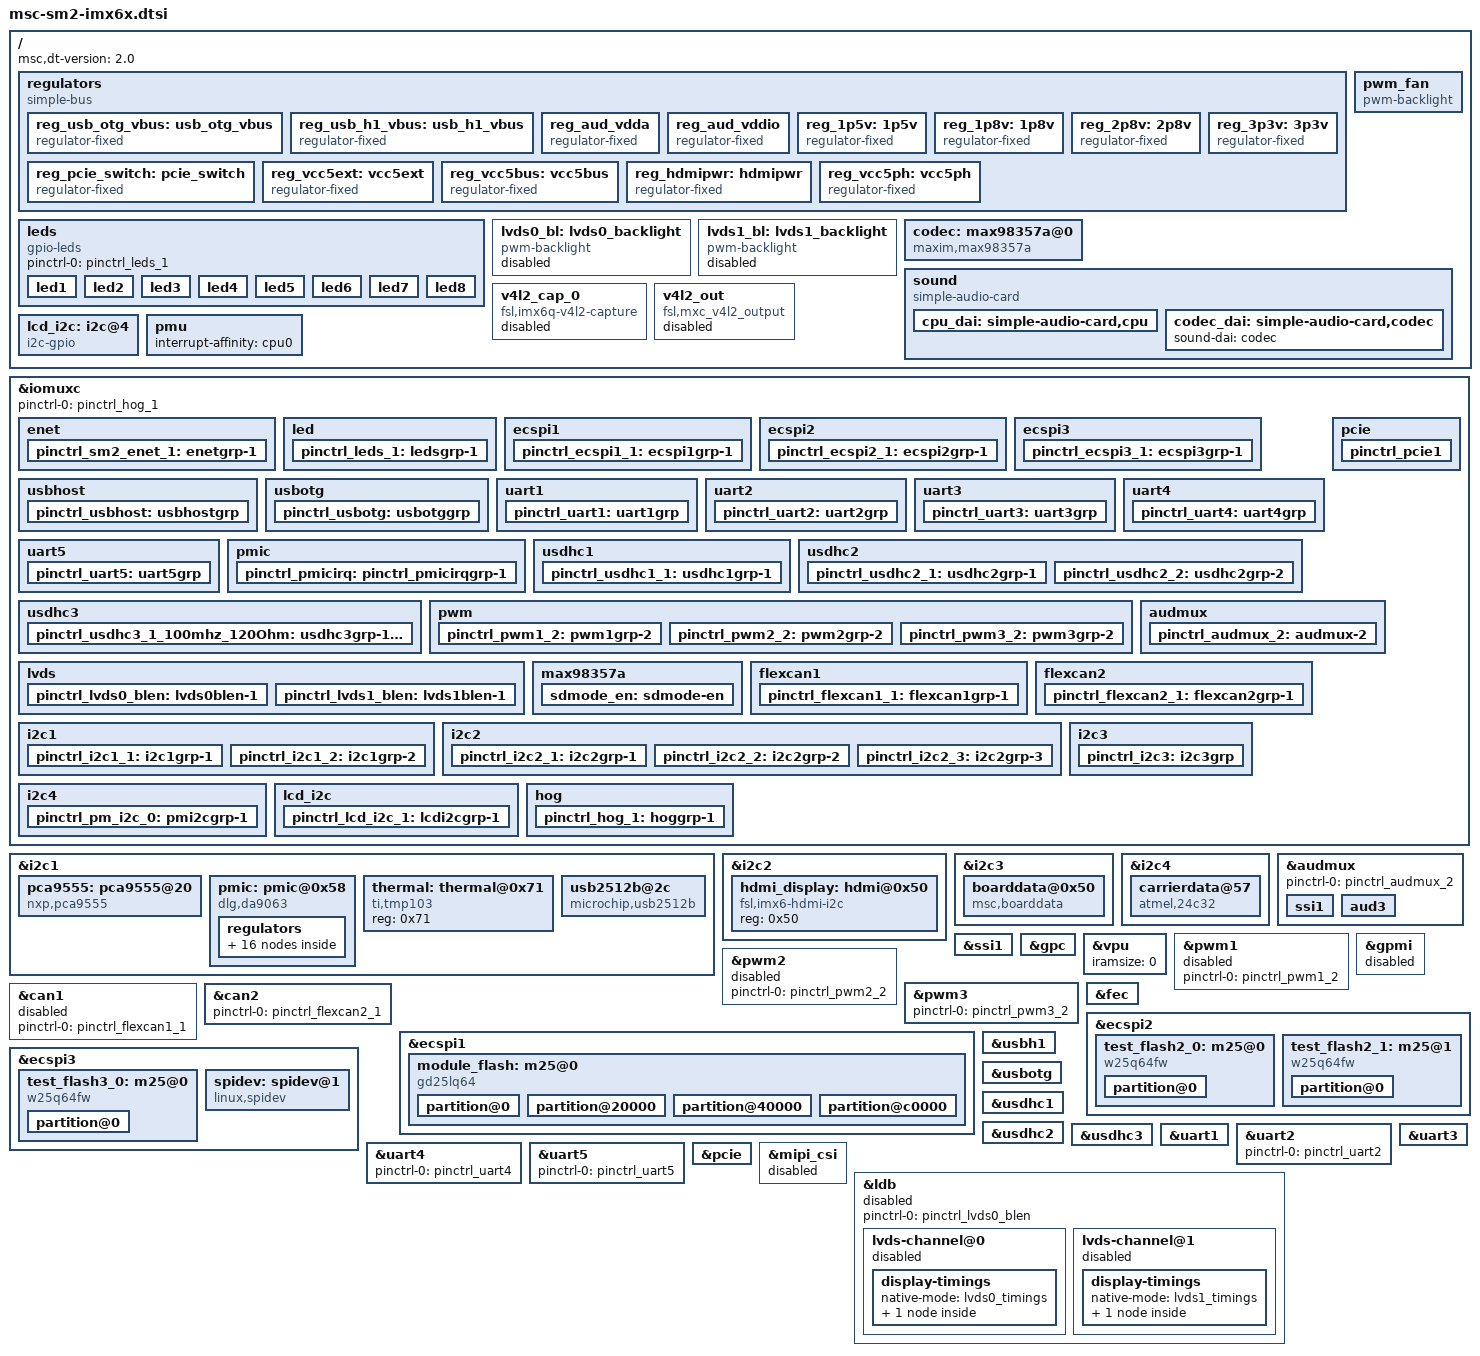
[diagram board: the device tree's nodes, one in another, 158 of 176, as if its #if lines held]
/*
 * Copyright 2017 MSC Technologies GmbH
 *
 * The code contained herein is licensed under the GNU General Public
 * License. You may obtain a copy of the GNU General Public License
 * Version 2 or later at the following locations:
 *
 * http://www.opensource.org/licenses/gpl-license.html
 * http://www.gnu.org/copyleft/gpl.html
 */

#include "skeleton.dtsi"
#include <dt-bindings/gpio/gpio.h>
#include <dt-bindings/sound/fsl-imx-audmux.h>


/* TODO: Find a suitable place for the macros below */
#define IMX_NO_PAD_CTL		(1 << 31)	/* Handled by mux driver: No pin config need */
#define IMX_PAD_SION		(1 << 30)	/* Handled by mux driver: Set SION */

#define PAD__HYS__DIS		(0 << 16)	/* CMOS input */
#define PAD__HYS__EN		(1 << 16)	/* Scmhitt trigger input */

#define PAD__PUS__100K_OHM_PD	(0 << 14)	/* 100K Ohm pull down */
#define PAD__PUS__47K_OHM_PU	(1 << 14)	/*  47K Ohm pull up */
#define PAD__PUS__100K_OHM_PU	(2 << 14)	/* 100K Ohm pull up */
#define PAD__PUS__22K_OHM_PU	(3 << 14)	/*  22K Ohm pull up */

#define PAD__PUE__KEEP		(0 << 13)	/* Keeper enabled */
#define PAD__PUE__PULL		(1 << 13)	/* Pull enabled */

#define PAD__PKE__DIS		(0 << 12)	/* Pull/Keeper disabled */
#define PAD__PKE__EN		(1 << 12)	/* Pull/Keeper enabled */

#define PAD__ODE__DIS		(0 << 11)	/* Output is CMOS */
#define PAD__ODE__EN		(1 << 11)	/* Output is Open Drain */

#define PAD__SPEED__LOW		(0 <<  6)	/*  50 MHz (SRE=x) */
#define PAD__SPEED__MEDIUM1	(1 <<  6)	/* 100 MHz, if SRE=1: 100MHz @ 1.8V, 150MHz @ 3.3V */
#define PAD__SPEED__MEDIUM2	(2 <<  6)	/* 100 MHz, if SRE=1: 100MHz @ 1.8V, 150MHz @ 3.3V */
#define PAD__SPEED__MAXIMUM	(3 <<  6)	/* 100 MHz, if SRE=1: 150MHz @ 1.8V, 100MHz @ 3.3V */

#define PAD__DSE__HIZ		(0 <<  3)	/* Hi-Z */
#define PAD__DSE__260_OHM	(1 <<  3)	/* 157 Ohm @ 3.3V, 260 Ohm @ 1.8V */
#define PAD__DSE__130_OHM	(2 <<  3)	/*  78 Ohm @ 3.3V, 130 Ohm @ 1.8V */
#define PAD__DSE__88_OHM	(3 <<  3)	/*  53 Ohm @ 3.3V,  88 Ohm @ 1.8V */
#define PAD__DSE__65_OHM	(4 <<  3)	/*  39 Ohm @ 3.3V,  65 Ohm @ 1.8V */
#define PAD__DSE__52_OHM	(5 <<  3)	/*  32 Ohm @ 3.3V,  52 Ohm @ 1.8V */
#define PAD__DSE__43_OHM	(6 <<  3)	/*  26 Ohm @ 3.3V,  43 Ohm @ 1.8V */
#define PAD__DSE__37_OHM	(7 <<  3)	/*  23 Ohm @ 3.3V,  37 Ohm @ 1.8V */

#define PAD__SRE__SLOW		(0 <<  0)	/* Slow slew rate */
#define PAD__SRE__FAST		(1 <<  0)	/* Fast slew rate */


&iomuxc {
	enet {
		pinctrl_sm2_enet_1: enetgrp-1 {
			fsl,pins = <
				MX6QDL_PAD_ENET_MDIO__ENET_MDIO		(PAD__HYS__EN  | PAD__PUS__100K_OHM_PU | PAD__PUE__PULL | PAD__PKE__EN  | PAD__ODE__DIS | PAD__SPEED__MEDIUM2 | PAD__DSE__43_OHM  | PAD__SRE__SLOW)
				MX6QDL_PAD_ENET_MDC__ENET_MDC		(PAD__HYS__EN  | PAD__PUS__100K_OHM_PU | PAD__PUE__PULL | PAD__PKE__EN  | PAD__ODE__DIS | PAD__SPEED__MEDIUM2 | PAD__DSE__43_OHM  | PAD__SRE__SLOW)
				MX6QDL_PAD_RGMII_TXC__RGMII_TXC		(PAD__HYS__EN  | PAD__PUS__100K_OHM_PU | PAD__PUE__PULL | PAD__PKE__EN  | PAD__ODE__DIS | PAD__SPEED__MEDIUM2 | PAD__DSE__43_OHM  | PAD__SRE__SLOW)
				MX6QDL_PAD_RGMII_TD0__RGMII_TD0		(PAD__HYS__EN  | PAD__PUS__100K_OHM_PU | PAD__PUE__PULL | PAD__PKE__EN  | PAD__ODE__DIS | PAD__SPEED__MEDIUM2 | PAD__DSE__43_OHM  | PAD__SRE__SLOW)
				MX6QDL_PAD_RGMII_TD1__RGMII_TD1		(PAD__HYS__EN  | PAD__PUS__100K_OHM_PU | PAD__PUE__PULL | PAD__PKE__EN  | PAD__ODE__DIS | PAD__SPEED__MEDIUM2 | PAD__DSE__43_OHM  | PAD__SRE__SLOW)
				MX6QDL_PAD_RGMII_TD2__RGMII_TD2		(PAD__HYS__EN  | PAD__PUS__100K_OHM_PU | PAD__PUE__PULL | PAD__PKE__EN  | PAD__ODE__DIS | PAD__SPEED__MEDIUM2 | PAD__DSE__43_OHM  | PAD__SRE__SLOW)
				MX6QDL_PAD_RGMII_TD3__RGMII_TD3		(PAD__HYS__EN  | PAD__PUS__100K_OHM_PU | PAD__PUE__PULL | PAD__PKE__EN  | PAD__ODE__DIS | PAD__SPEED__MEDIUM2 | PAD__DSE__43_OHM  | PAD__SRE__SLOW)
				MX6QDL_PAD_RGMII_TX_CTL__RGMII_TX_CTL	(PAD__HYS__EN  | PAD__PUS__100K_OHM_PU | PAD__PUE__PULL | PAD__PKE__EN  | PAD__ODE__DIS | PAD__SPEED__MEDIUM2 | PAD__DSE__43_OHM  | PAD__SRE__SLOW)
				MX6QDL_PAD_ENET_REF_CLK__ENET_TX_CLK	(PAD__HYS__EN  | PAD__PUS__100K_OHM_PD | PAD__PUE__KEEP | PAD__PKE__DIS | PAD__ODE__DIS | PAD__SPEED__MEDIUM2 | PAD__DSE__43_OHM  | PAD__SRE__SLOW)
				MX6QDL_PAD_RGMII_RXC__RGMII_RXC		(PAD__HYS__EN  | PAD__PUS__100K_OHM_PU | PAD__PUE__PULL | PAD__PKE__EN  | PAD__ODE__DIS | PAD__SPEED__MEDIUM2 | PAD__DSE__43_OHM  | PAD__SRE__SLOW)
				MX6QDL_PAD_RGMII_RD0__RGMII_RD0		(PAD__HYS__EN  | PAD__PUS__100K_OHM_PU | PAD__PUE__PULL | PAD__PKE__EN  | PAD__ODE__DIS | PAD__SPEED__MEDIUM2 | PAD__DSE__43_OHM  | PAD__SRE__SLOW)
				MX6QDL_PAD_RGMII_RD1__RGMII_RD1		(PAD__HYS__EN  | PAD__PUS__100K_OHM_PU | PAD__PUE__PULL | PAD__PKE__EN  | PAD__ODE__DIS | PAD__SPEED__MEDIUM2 | PAD__DSE__43_OHM  | PAD__SRE__SLOW)
				MX6QDL_PAD_RGMII_RD2__RGMII_RD2		(PAD__HYS__EN  | PAD__PUS__100K_OHM_PU | PAD__PUE__PULL | PAD__PKE__EN  | PAD__ODE__DIS | PAD__SPEED__MEDIUM2 | PAD__DSE__43_OHM  | PAD__SRE__SLOW)
				MX6QDL_PAD_RGMII_RD3__RGMII_RD3		(PAD__HYS__EN  | PAD__PUS__100K_OHM_PU | PAD__PUE__PULL | PAD__PKE__EN  | PAD__ODE__DIS | PAD__SPEED__MEDIUM2 | PAD__DSE__43_OHM  | PAD__SRE__SLOW)
				MX6QDL_PAD_RGMII_RX_CTL__RGMII_RX_CTL	(PAD__HYS__EN  | PAD__PUS__100K_OHM_PU | PAD__PUE__PULL | PAD__PKE__EN  | PAD__ODE__DIS | PAD__SPEED__MEDIUM2 | PAD__DSE__43_OHM  | PAD__SRE__SLOW)
			>;
		};
	};

	led {
		pinctrl_leds_1: ledsgrp-1 {
			fsl,pins = <
				MX6QDL_PAD_NANDF_D3__GPIO2_IO03		(PAD__HYS__DIS | PAD__PUS__100K_OHM_PD | PAD__PUE__KEEP | PAD__PKE__DIS | PAD__ODE__DIS | PAD__SPEED__LOW     | PAD__DSE__HIZ     | PAD__SRE__SLOW | IMX_NO_PAD_CTL)	/* DEBUG_0 on SoM debug connector */
				MX6QDL_PAD_NANDF_D4__GPIO2_IO04		(PAD__HYS__DIS | PAD__PUS__100K_OHM_PD | PAD__PUE__KEEP | PAD__PKE__DIS | PAD__ODE__DIS | PAD__SPEED__LOW     | PAD__DSE__HIZ     | PAD__SRE__SLOW | IMX_NO_PAD_CTL)	/* DEBUG_1 on SoM debug connector */
				MX6QDL_PAD_NANDF_D5__GPIO2_IO05		(PAD__HYS__DIS | PAD__PUS__100K_OHM_PD | PAD__PUE__KEEP | PAD__PKE__DIS | PAD__ODE__DIS | PAD__SPEED__LOW     | PAD__DSE__HIZ     | PAD__SRE__SLOW | IMX_NO_PAD_CTL)	/* DEBUG_2 on SoM debug connector */
				MX6QDL_PAD_ENET_CRS_DV__GPIO1_IO25	(PAD__HYS__DIS | PAD__PUS__100K_OHM_PD | PAD__PUE__KEEP | PAD__PKE__DIS | PAD__ODE__DIS | PAD__SPEED__LOW     | PAD__DSE__HIZ     | PAD__SRE__SLOW | IMX_NO_PAD_CTL)	/* iMX6 U21,                             Linux GPIO  25, SoM Orange LED */
				MX6QDL_PAD_KEY_COL1__GPIO4_IO08		(PAD__HYS__DIS | PAD__PUS__100K_OHM_PD | PAD__PUE__KEEP | PAD__PKE__DIS | PAD__ODE__DIS | PAD__SPEED__LOW     | PAD__DSE__HIZ     | PAD__SRE__SLOW | IMX_NO_PAD_CTL)	/* iMX6  U7, SoM  S54, SMARC2 SATA_ACT#, Linux GPIO 104 */
				MX6QDL_PAD_EIM_D29__GPIO3_IO29		(PAD__HYS__DIS | PAD__PUS__100K_OHM_PD | PAD__PUE__PULL | PAD__PKE__EN  | PAD__ODE__DIS | PAD__SPEED__MEDIUM2 | PAD__DSE__43_OHM  | PAD__SRE__FAST)		/* iMX6 J19, SoM P108, SMARC2 GPIO0,     Linux GPIO  93, Carrier board LED0 */
				MX6QDL_PAD_GPIO_16__GPIO7_IO11		(PAD__HYS__DIS | PAD__PUS__100K_OHM_PD | PAD__PUE__PULL | PAD__PKE__EN  | PAD__ODE__DIS | PAD__SPEED__MEDIUM2 | PAD__DSE__43_OHM  | PAD__SRE__FAST)		/* iMX6  R2, SoM P109, SMARC2 GPIO1,     Linux GPIO 203, Carrier board LED1 */
				MX6QDL_PAD_EIM_D28__GPIO3_IO28		(PAD__HYS__DIS | PAD__PUS__100K_OHM_PD | PAD__PUE__PULL | PAD__PKE__EN  | PAD__ODE__DIS | PAD__SPEED__MEDIUM2 | PAD__DSE__43_OHM  | PAD__SRE__FAST)		/* iMX6 G23, SoM P110, SMARC2 GPIO2,     Linux GPIO  92, Carrier board LED2 */
			>;
		};
	};

	ecspi1 {
		pinctrl_ecspi1_1: ecspi1grp-1 {
			fsl,pins = <
				MX6QDL_PAD_EIM_D17__ECSPI1_MISO		(PAD__HYS__EN  | PAD__PUS__100K_OHM_PD | PAD__PUE__KEEP | PAD__PKE__DIS | PAD__ODE__DIS | PAD__SPEED__MEDIUM2 | PAD__DSE__43_OHM  | PAD__SRE__FAST)
				MX6QDL_PAD_EIM_D18__ECSPI1_MOSI		(PAD__HYS__EN  | PAD__PUS__100K_OHM_PD | PAD__PUE__KEEP | PAD__PKE__DIS | PAD__ODE__DIS | PAD__SPEED__MEDIUM2 | PAD__DSE__43_OHM  | PAD__SRE__FAST)
				MX6QDL_PAD_EIM_D16__ECSPI1_SCLK		(PAD__HYS__EN  | PAD__PUS__100K_OHM_PD | PAD__PUE__KEEP | PAD__PKE__DIS | PAD__ODE__DIS | PAD__SPEED__MEDIUM2 | PAD__DSE__43_OHM  | PAD__SRE__FAST)
				MX6QDL_PAD_EIM_EB2__GPIO2_IO30		(PAD__HYS__DIS | PAD__PUS__100K_OHM_PD | PAD__PUE__PULL | PAD__PKE__EN  | PAD__ODE__DIS | PAD__SPEED__MEDIUM2 | PAD__DSE__43_OHM  | PAD__SRE__FAST)		/* SPI1_SS0n */
			>;
		};
	};

	ecspi2 {
		pinctrl_ecspi2_1: ecspi2grp-1 {
			fsl,pins = <
				MX6QDL_PAD_EIM_OE__ECSPI2_MISO		(PAD__HYS__EN  | PAD__PUS__100K_OHM_PD | PAD__PUE__KEEP | PAD__PKE__DIS | PAD__ODE__DIS | PAD__SPEED__MEDIUM2 | PAD__DSE__43_OHM  | PAD__SRE__FAST)
				MX6QDL_PAD_EIM_CS1__ECSPI2_MOSI		(PAD__HYS__EN  | PAD__PUS__100K_OHM_PD | PAD__PUE__KEEP | PAD__PKE__DIS | PAD__ODE__DIS | PAD__SPEED__MEDIUM2 | PAD__DSE__43_OHM  | PAD__SRE__FAST)
				MX6QDL_PAD_EIM_CS0__ECSPI2_SCLK		(PAD__HYS__EN  | PAD__PUS__100K_OHM_PD | PAD__PUE__KEEP | PAD__PKE__DIS | PAD__ODE__DIS | PAD__SPEED__MEDIUM2 | PAD__DSE__43_OHM  | PAD__SRE__FAST)
				MX6QDL_PAD_DISP0_DAT18__GPIO5_IO12	(PAD__HYS__DIS | PAD__PUS__100K_OHM_PD | PAD__PUE__PULL | PAD__PKE__EN  | PAD__ODE__DIS | PAD__SPEED__MEDIUM2 | PAD__DSE__43_OHM  | PAD__SRE__FAST)		/* SPI2_SS0n */
				MX6QDL_PAD_DISP0_DAT15__GPIO5_IO09	(PAD__HYS__DIS | PAD__PUS__100K_OHM_PD | PAD__PUE__PULL | PAD__PKE__EN  | PAD__ODE__DIS | PAD__SPEED__MEDIUM2 | PAD__DSE__43_OHM  | PAD__SRE__FAST)		/* SPI2_SS1n */
			>;
		};
	};

	ecspi3 {
		pinctrl_ecspi3_1: ecspi3grp-1 {
			fsl,pins = <
				MX6QDL_PAD_DISP0_DAT2__ECSPI3_MISO	(PAD__HYS__EN  | PAD__PUS__100K_OHM_PD | PAD__PUE__KEEP | PAD__PKE__DIS | PAD__ODE__DIS | PAD__SPEED__MEDIUM2 | PAD__DSE__43_OHM  | PAD__SRE__FAST)
				MX6QDL_PAD_DISP0_DAT1__ECSPI3_MOSI	(PAD__HYS__EN  | PAD__PUS__100K_OHM_PD | PAD__PUE__KEEP | PAD__PKE__DIS | PAD__ODE__DIS | PAD__SPEED__MEDIUM2 | PAD__DSE__43_OHM  | PAD__SRE__FAST)
				MX6QDL_PAD_DISP0_DAT0__ECSPI3_SCLK	(PAD__HYS__EN  | PAD__PUS__100K_OHM_PD | PAD__PUE__KEEP | PAD__PKE__DIS | PAD__ODE__DIS | PAD__SPEED__MEDIUM2 | PAD__DSE__43_OHM  | PAD__SRE__FAST)
				MX6QDL_PAD_DISP0_DAT3__GPIO4_IO24	(PAD__HYS__DIS | PAD__PUS__100K_OHM_PD | PAD__PUE__PULL | PAD__PKE__EN  | PAD__ODE__DIS | PAD__SPEED__MEDIUM2 | PAD__DSE__43_OHM  | PAD__SRE__FAST)		/* SPI3_SS0n */
				MX6QDL_PAD_DISP0_DAT4__GPIO4_IO25	(PAD__HYS__DIS | PAD__PUS__100K_OHM_PD | PAD__PUE__PULL | PAD__PKE__EN  | PAD__ODE__DIS | PAD__SPEED__MEDIUM2 | PAD__DSE__43_OHM  | PAD__SRE__FAST)		/* SPI3_SS1n */
			>;
		};
	};

	usbhost {
		pinctrl_usbhost: usbhostgrp {
			fsl,pins = <
				MX6QDL_PAD_GPIO_0__GPIO1_IO00		(PAD__HYS__EN  | PAD__PUS__100K_OHM_PU | PAD__PUE__PULL | PAD__PKE__EN  | PAD__ODE__EN  | PAD__SPEED__MEDIUM2 | PAD__DSE__43_OHM  | PAD__SRE__FAST)		/* iMX6 T5, SoM P67, SMARC2 USB1_EN_OC#, Linux GPIO 0, Output to switch external power enable */
				MX6QDL_PAD_GPIO_3__XTALOSC_REF_CLK_24M	(PAD__HYS__EN  | PAD__PUS__100K_OHM_PU | PAD__PUE__PULL | PAD__PKE__EN  | PAD__ODE__DIS | PAD__SPEED__LOW     | PAD__DSE__43_OHM  | PAD__SRE__SLOW)		/* USB_REFCLK */
				MX6QDL_PAD_EIM_D30__GPIO3_IO30		(PAD__HYS__EN  | PAD__PUS__100K_OHM_PU | PAD__PUE__PULL | PAD__PKE__EN  | PAD__ODE__EN  | PAD__SPEED__MEDIUM2 | PAD__DSE__43_OHM  | PAD__SRE__FAST)		/* iMX6 J20, SoM P67, SMARC2 USB1_EN_OC#, Linux GPIO 94, Input to monitor external power over-current */
			>;
		};
	};

	usbotg {
		pinctrl_usbotg: usbotggrp {
			fsl,pins = <
				MX6QDL_PAD_EIM_D22__GPIO3_IO22		(PAD__HYS__DIS | PAD__PUS__100K_OHM_PD | PAD__PUE__PULL | PAD__PKE__EN  | PAD__ODE__DIS | PAD__SPEED__MEDIUM2 | PAD__DSE__43_OHM  | PAD__SRE__FAST)		/* OTG_DRVVBUS */
				MX6QDL_PAD_ENET_RX_ER__USB_OTG_ID	(PAD__HYS__EN  | PAD__PUS__47K_OHM_PU  | PAD__PUE__PULL | PAD__PKE__EN  | PAD__ODE__DIS | PAD__SPEED__MEDIUM1 | PAD__DSE__88_OHM  | PAD__SRE__FAST)
				MX6QDL_PAD_EIM_D21__USB_OTG_OC		(PAD__HYS__EN  | PAD__PUS__100K_OHM_PU | PAD__PUE__PULL | PAD__PKE__EN  | PAD__ODE__DIS | PAD__SPEED__MEDIUM2 | PAD__DSE__43_OHM  | PAD__SRE__SLOW)
			>;
		};
	};

	uart1 {
		pinctrl_uart1: uart1grp {
			fsl,pins = <
				MX6QDL_PAD_CSI0_DAT10__UART1_TX_DATA	(PAD__HYS__EN  | PAD__PUS__100K_OHM_PU | PAD__PUE__PULL | PAD__PKE__EN  | PAD__ODE__DIS | PAD__SPEED__MEDIUM2 | PAD__DSE__43_OHM  | PAD__SRE__FAST)
				MX6QDL_PAD_CSI0_DAT11__UART1_RX_DATA	(PAD__HYS__EN  | PAD__PUS__100K_OHM_PU | PAD__PUE__PULL | PAD__PKE__EN  | PAD__ODE__DIS | PAD__SPEED__MEDIUM2 | PAD__DSE__43_OHM  | PAD__SRE__FAST)
				MX6QDL_PAD_EIM_D19__UART1_CTS_B		(PAD__HYS__EN  | PAD__PUS__100K_OHM_PU | PAD__PUE__PULL | PAD__PKE__EN  | PAD__ODE__DIS | PAD__SPEED__MEDIUM2 | PAD__DSE__43_OHM  | PAD__SRE__FAST)
				MX6QDL_PAD_EIM_D20__UART1_RTS_B		(PAD__HYS__EN  | PAD__PUS__100K_OHM_PU | PAD__PUE__PULL | PAD__PKE__EN  | PAD__ODE__DIS | PAD__SPEED__MEDIUM2 | PAD__DSE__43_OHM  | PAD__SRE__FAST)
			>;
		};
	};

	uart2 {
		pinctrl_uart2: uart2grp {
			fsl,pins = <
				MX6QDL_PAD_EIM_D26__UART2_TX_DATA	(PAD__HYS__EN  | PAD__PUS__100K_OHM_PU | PAD__PUE__PULL | PAD__PKE__EN  | PAD__ODE__DIS | PAD__SPEED__MEDIUM2 | PAD__DSE__43_OHM  | PAD__SRE__FAST)
				MX6QDL_PAD_EIM_D27__UART2_RX_DATA	(PAD__HYS__EN  | PAD__PUS__100K_OHM_PU | PAD__PUE__PULL | PAD__PKE__EN  | PAD__ODE__DIS | PAD__SPEED__MEDIUM2 | PAD__DSE__43_OHM  | PAD__SRE__FAST)
			>;
		};
	};

	uart3 {
		pinctrl_uart3: uart3grp {
			fsl,pins = <
				MX6QDL_PAD_EIM_D24__UART3_TX_DATA	(PAD__HYS__EN  | PAD__PUS__100K_OHM_PU | PAD__PUE__PULL | PAD__PKE__EN  | PAD__ODE__DIS | PAD__SPEED__MEDIUM2 | PAD__DSE__43_OHM  | PAD__SRE__FAST)
				MX6QDL_PAD_EIM_D25__UART3_RX_DATA	(PAD__HYS__EN  | PAD__PUS__100K_OHM_PU | PAD__PUE__PULL | PAD__PKE__EN  | PAD__ODE__DIS | PAD__SPEED__MEDIUM2 | PAD__DSE__43_OHM  | PAD__SRE__FAST)
				MX6QDL_PAD_EIM_D23__UART3_CTS_B		(PAD__HYS__EN  | PAD__PUS__100K_OHM_PU | PAD__PUE__PULL | PAD__PKE__EN  | PAD__ODE__DIS | PAD__SPEED__MEDIUM2 | PAD__DSE__43_OHM  | PAD__SRE__FAST)
				MX6QDL_PAD_EIM_D31__UART3_RTS_B		(PAD__HYS__EN  | PAD__PUS__100K_OHM_PU | PAD__PUE__PULL | PAD__PKE__EN  | PAD__ODE__DIS | PAD__SPEED__MEDIUM2 | PAD__DSE__43_OHM  | PAD__SRE__FAST)
			>;
		};
	};

	uart4 {
		pinctrl_uart4: uart4grp {
			fsl,pins = <
				MX6QDL_PAD_KEY_COL0__UART4_TX_DATA	(PAD__HYS__EN  | PAD__PUS__100K_OHM_PU | PAD__PUE__PULL | PAD__PKE__EN  | PAD__ODE__DIS | PAD__SPEED__MEDIUM2 | PAD__DSE__43_OHM  | PAD__SRE__FAST)
				MX6QDL_PAD_KEY_ROW0__UART4_RX_DATA	(PAD__HYS__EN  | PAD__PUS__100K_OHM_PU | PAD__PUE__PULL | PAD__PKE__EN  | PAD__ODE__DIS | PAD__SPEED__MEDIUM2 | PAD__DSE__43_OHM  | PAD__SRE__FAST)
			>;
		};
	};

	uart5 {
		pinctrl_uart5: uart5grp {
			fsl,pins = <
				MX6QDL_PAD_CSI0_DAT14__UART5_TX_DATA	(PAD__HYS__EN  | PAD__PUS__100K_OHM_PU | PAD__PUE__PULL | PAD__PKE__EN  | PAD__ODE__DIS | PAD__SPEED__MEDIUM2 | PAD__DSE__43_OHM  | PAD__SRE__FAST)
				MX6QDL_PAD_CSI0_DAT15__UART5_RX_DATA	(PAD__HYS__EN  | PAD__PUS__100K_OHM_PU | PAD__PUE__PULL | PAD__PKE__EN  | PAD__ODE__DIS | PAD__SPEED__MEDIUM2 | PAD__DSE__43_OHM  | PAD__SRE__FAST)
			>;
		};
	};

	pmic {
		pinctrl_pmicirq: pinctrl_pmicirqgrp-1 {
			fsl,pins = <
				MX6QDL_PAD_GPIO_4__GPIO1_IO04		(PAD__HYS__EN  | PAD__PUS__22K_OHM_PU  | PAD__PUE__PULL | PAD__PKE__EN  | PAD__ODE__DIS | PAD__SPEED__MEDIUM2 | PAD__DSE__43_OHM  | PAD__SRE__SLOW)
			>;
		};
	};

	usdhc1 {
		pinctrl_usdhc1_1: usdhc1grp-1 {
			fsl,pins = <
				MX6QDL_PAD_SD1_CMD__SD1_CMD		(PAD__HYS__EN  | PAD__PUS__47K_OHM_PU  | PAD__PUE__PULL | PAD__PKE__EN  | PAD__ODE__DIS | PAD__SPEED__MEDIUM1 | PAD__DSE__43_OHM  | PAD__SRE__FAST)
				MX6QDL_PAD_SD1_CLK__SD1_CLK		(PAD__HYS__EN  | PAD__PUS__100K_OHM_PD | PAD__PUE__KEEP | PAD__PKE__DIS | PAD__ODE__DIS | PAD__SPEED__MEDIUM1 | PAD__DSE__43_OHM  | PAD__SRE__FAST)
				MX6QDL_PAD_SD1_DAT0__SD1_DATA0		(PAD__HYS__EN  | PAD__PUS__47K_OHM_PU  | PAD__PUE__PULL | PAD__PKE__EN  | PAD__ODE__DIS | PAD__SPEED__MEDIUM1 | PAD__DSE__43_OHM  | PAD__SRE__FAST)
				MX6QDL_PAD_SD1_DAT1__SD1_DATA1		(PAD__HYS__EN  | PAD__PUS__47K_OHM_PU  | PAD__PUE__PULL | PAD__PKE__EN  | PAD__ODE__DIS | PAD__SPEED__MEDIUM1 | PAD__DSE__43_OHM  | PAD__SRE__FAST)
				MX6QDL_PAD_SD1_DAT2__SD1_DATA2		(PAD__HYS__EN  | PAD__PUS__47K_OHM_PU  | PAD__PUE__PULL | PAD__PKE__EN  | PAD__ODE__DIS | PAD__SPEED__MEDIUM1 | PAD__DSE__43_OHM  | PAD__SRE__FAST)
				MX6QDL_PAD_SD1_DAT3__SD1_DATA3		(PAD__HYS__EN  | PAD__PUS__47K_OHM_PU  | PAD__PUE__PULL | PAD__PKE__EN  | PAD__ODE__DIS | PAD__SPEED__MEDIUM1 | PAD__DSE__43_OHM  | PAD__SRE__FAST)
			>;
		};
	};

	usdhc2 {
		pinctrl_usdhc2_1: usdhc2grp-1 {
			fsl,pins = <
				MX6QDL_PAD_SD2_CMD__SD2_CMD		(PAD__HYS__EN  | PAD__PUS__47K_OHM_PU  | PAD__PUE__PULL | PAD__PKE__EN  | PAD__ODE__DIS | PAD__SPEED__MEDIUM1 | PAD__DSE__88_OHM  | PAD__SRE__FAST)
				MX6QDL_PAD_SD2_CLK__SD2_CLK		(PAD__HYS__EN  | PAD__PUS__100K_OHM_PD | PAD__PUE__KEEP | PAD__PKE__DIS | PAD__ODE__DIS | PAD__SPEED__MEDIUM1 | PAD__DSE__88_OHM  | PAD__SRE__FAST)
				MX6QDL_PAD_SD2_DAT0__SD2_DATA0		(PAD__HYS__EN  | PAD__PUS__47K_OHM_PU  | PAD__PUE__PULL | PAD__PKE__EN  | PAD__ODE__DIS | PAD__SPEED__MEDIUM1 | PAD__DSE__88_OHM  | PAD__SRE__FAST)
				MX6QDL_PAD_SD2_DAT1__SD2_DATA1		(PAD__HYS__EN  | PAD__PUS__47K_OHM_PU  | PAD__PUE__PULL | PAD__PKE__EN  | PAD__ODE__DIS | PAD__SPEED__MEDIUM1 | PAD__DSE__88_OHM  | PAD__SRE__FAST)
				MX6QDL_PAD_SD2_DAT2__SD2_DATA2		(PAD__HYS__EN  | PAD__PUS__47K_OHM_PU  | PAD__PUE__PULL | PAD__PKE__EN  | PAD__ODE__DIS | PAD__SPEED__MEDIUM1 | PAD__DSE__88_OHM  | PAD__SRE__FAST)
				MX6QDL_PAD_SD2_DAT3__SD2_DATA3		(PAD__HYS__EN  | PAD__PUS__47K_OHM_PU  | PAD__PUE__PULL | PAD__PKE__EN  | PAD__ODE__DIS | PAD__SPEED__MEDIUM1 | PAD__DSE__88_OHM  | PAD__SRE__FAST)
				MX6QDL_PAD_NANDF_D4__SD2_DATA4		(PAD__HYS__EN  | PAD__PUS__47K_OHM_PU  | PAD__PUE__PULL | PAD__PKE__EN  | PAD__ODE__DIS | PAD__SPEED__MEDIUM1 | PAD__DSE__88_OHM  | PAD__SRE__FAST)
				MX6QDL_PAD_NANDF_D5__SD2_DATA5		(PAD__HYS__EN  | PAD__PUS__47K_OHM_PU  | PAD__PUE__PULL | PAD__PKE__EN  | PAD__ODE__DIS | PAD__SPEED__MEDIUM1 | PAD__DSE__88_OHM  | PAD__SRE__FAST)
				MX6QDL_PAD_NANDF_D6__SD2_DATA6		(PAD__HYS__EN  | PAD__PUS__47K_OHM_PU  | PAD__PUE__PULL | PAD__PKE__EN  | PAD__ODE__DIS | PAD__SPEED__MEDIUM1 | PAD__DSE__88_OHM  | PAD__SRE__FAST)
				MX6QDL_PAD_NANDF_D7__SD2_DATA7		(PAD__HYS__EN  | PAD__PUS__47K_OHM_PU  | PAD__PUE__PULL | PAD__PKE__EN  | PAD__ODE__DIS | PAD__SPEED__MEDIUM1 | PAD__DSE__88_OHM  | PAD__SRE__FAST)
			>;
		};

		pinctrl_usdhc2_2: usdhc2grp-2 {
			fsl,pins = <
				MX6QDL_PAD_SD2_CMD__SD2_CMD		(PAD__HYS__EN  | PAD__PUS__47K_OHM_PU  | PAD__PUE__PULL | PAD__PKE__EN  | PAD__ODE__DIS | PAD__SPEED__MEDIUM1 | PAD__DSE__88_OHM  | PAD__SRE__FAST)
				MX6QDL_PAD_SD2_CLK__SD2_CLK		(PAD__HYS__EN  | PAD__PUS__100K_OHM_PD | PAD__PUE__KEEP | PAD__PKE__DIS | PAD__ODE__DIS | PAD__SPEED__MEDIUM1 | PAD__DSE__88_OHM  | PAD__SRE__FAST)
				MX6QDL_PAD_SD2_DAT0__SD2_DATA0		(PAD__HYS__EN  | PAD__PUS__47K_OHM_PU  | PAD__PUE__PULL | PAD__PKE__EN  | PAD__ODE__DIS | PAD__SPEED__MEDIUM1 | PAD__DSE__88_OHM  | PAD__SRE__FAST)
				MX6QDL_PAD_SD2_DAT1__SD2_DATA1		(PAD__HYS__EN  | PAD__PUS__47K_OHM_PU  | PAD__PUE__PULL | PAD__PKE__EN  | PAD__ODE__DIS | PAD__SPEED__MEDIUM1 | PAD__DSE__88_OHM  | PAD__SRE__FAST)
				MX6QDL_PAD_SD2_DAT2__SD2_DATA2		(PAD__HYS__EN  | PAD__PUS__47K_OHM_PU  | PAD__PUE__PULL | PAD__PKE__EN  | PAD__ODE__DIS | PAD__SPEED__MEDIUM1 | PAD__DSE__88_OHM  | PAD__SRE__FAST)
				MX6QDL_PAD_SD2_DAT3__SD2_DATA3		(PAD__HYS__EN  | PAD__PUS__47K_OHM_PU  | PAD__PUE__PULL | PAD__PKE__EN  | PAD__ODE__DIS | PAD__SPEED__MEDIUM1 | PAD__DSE__88_OHM  | PAD__SRE__FAST)
			>;
		};
	};

	usdhc3 {
		pinctrl_usdhc3_1_100mhz_120Ohm: usdhc3grp-1-100mhz {
			fsl,pins = <
				MX6QDL_PAD_SD3_CMD__SD3_CMD		(PAD__HYS__EN  | PAD__PUS__47K_OHM_PU  | PAD__PUE__PULL | PAD__PKE__EN  | PAD__ODE__DIS | PAD__SPEED__LOW     | PAD__DSE__260_OHM | PAD__SRE__FAST)
				MX6QDL_PAD_SD3_CLK__SD3_CLK		(PAD__HYS__EN  | PAD__PUS__100K_OHM_PD | PAD__PUE__KEEP | PAD__PKE__DIS | PAD__ODE__DIS | PAD__SPEED__LOW     | PAD__DSE__260_OHM | PAD__SRE__FAST)
				MX6QDL_PAD_SD3_DAT0__SD3_DATA0		(PAD__HYS__EN  | PAD__PUS__47K_OHM_PU  | PAD__PUE__PULL | PAD__PKE__EN  | PAD__ODE__DIS | PAD__SPEED__LOW     | PAD__DSE__260_OHM | PAD__SRE__FAST)
				MX6QDL_PAD_SD3_DAT1__SD3_DATA1		(PAD__HYS__EN  | PAD__PUS__47K_OHM_PU  | PAD__PUE__PULL | PAD__PKE__EN  | PAD__ODE__DIS | PAD__SPEED__LOW     | PAD__DSE__260_OHM | PAD__SRE__FAST)
				MX6QDL_PAD_SD3_DAT2__SD3_DATA2		(PAD__HYS__EN  | PAD__PUS__47K_OHM_PU  | PAD__PUE__PULL | PAD__PKE__EN  | PAD__ODE__DIS | PAD__SPEED__LOW     | PAD__DSE__260_OHM | PAD__SRE__FAST)
				MX6QDL_PAD_SD3_DAT3__SD3_DATA3		(PAD__HYS__EN  | PAD__PUS__47K_OHM_PU  | PAD__PUE__PULL | PAD__PKE__EN  | PAD__ODE__DIS | PAD__SPEED__LOW     | PAD__DSE__260_OHM | PAD__SRE__FAST)
				MX6QDL_PAD_SD3_DAT4__SD3_DATA4		(PAD__HYS__EN  | PAD__PUS__47K_OHM_PU  | PAD__PUE__PULL | PAD__PKE__EN  | PAD__ODE__DIS | PAD__SPEED__LOW     | PAD__DSE__260_OHM | PAD__SRE__FAST)
				MX6QDL_PAD_SD3_DAT5__SD3_DATA5		(PAD__HYS__EN  | PAD__PUS__47K_OHM_PU  | PAD__PUE__PULL | PAD__PKE__EN  | PAD__ODE__DIS | PAD__SPEED__LOW     | PAD__DSE__260_OHM | PAD__SRE__FAST)
				MX6QDL_PAD_SD3_DAT6__SD3_DATA6		(PAD__HYS__EN  | PAD__PUS__47K_OHM_PU  | PAD__PUE__PULL | PAD__PKE__EN  | PAD__ODE__DIS | PAD__SPEED__LOW     | PAD__DSE__260_OHM | PAD__SRE__FAST)
				MX6QDL_PAD_SD3_DAT7__SD3_DATA7		(PAD__HYS__EN  | PAD__PUS__47K_OHM_PU  | PAD__PUE__PULL | PAD__PKE__EN  | PAD__ODE__DIS | PAD__SPEED__LOW     | PAD__DSE__260_OHM | PAD__SRE__FAST)
				MX6QDL_PAD_SD3_RST__SD3_RESET		(PAD__HYS__EN  | PAD__PUS__47K_OHM_PU  | PAD__PUE__PULL | PAD__PKE__EN  | PAD__ODE__DIS | PAD__SPEED__LOW     | PAD__DSE__260_OHM | PAD__SRE__FAST)
			>;
		};
	};

	pwm {
		pinctrl_pwm1_2: pwm1grp-2 {
			fsl,pins = <
				MX6QDL_PAD_GPIO_9__PWM1_OUT		(PAD__HYS__EN  | PAD__PUS__100K_OHM_PU | PAD__PUE__PULL | PAD__PKE__EN  | PAD__ODE__DIS | PAD__SPEED__MEDIUM2 | PAD__DSE__43_OHM  | PAD__SRE__FAST)
			>;
		};

		pinctrl_pwm2_2: pwm2grp-2 {
			fsl,pins = <
				MX6QDL_PAD_DISP0_DAT9__PWM2_OUT		(PAD__HYS__EN  | PAD__PUS__100K_OHM_PU | PAD__PUE__PULL | PAD__PKE__EN  | PAD__ODE__DIS | PAD__SPEED__MEDIUM2 | PAD__DSE__43_OHM  | PAD__SRE__FAST)
			>;
		};
#ifndef IMX6DL_ULTIMAKER
		pinctrl_pwm3_2: pwm3grp-2 {
			fsl,pins = <
				MX6QDL_PAD_SD4_DAT1__PWM3_OUT		(PAD__HYS__EN  | PAD__PUS__100K_OHM_PU | PAD__PUE__PULL | PAD__PKE__EN  | PAD__ODE__DIS | PAD__SPEED__MEDIUM2 | PAD__DSE__43_OHM  | PAD__SRE__FAST)
			>;
		};
#endif
	};

	lvds {
		pinctrl_lvds0_blen: lvds0blen-1 {
			fsl,pins = <
				MX6QDL_PAD_NANDF_CS2__GPIO6_IO15	(PAD__HYS__DIS | PAD__PUS__100K_OHM_PD | PAD__PUE__PULL | PAD__PKE__EN  | PAD__ODE__DIS | PAD__SPEED__MEDIUM2 | PAD__DSE__43_OHM  | PAD__SRE__FAST)		/* LCD_POW_EN */
				MX6QDL_PAD_EIM_BCLK__GPIO6_IO31		(PAD__HYS__DIS | PAD__PUS__100K_OHM_PD | PAD__PUE__PULL | PAD__PKE__EN  | PAD__ODE__DIS | PAD__SPEED__MEDIUM2 | PAD__DSE__43_OHM  | PAD__SRE__FAST)		/* BL_POW_EN */
			>;
		};

		pinctrl_lvds1_blen: lvds1blen-1 {
			fsl,pins = <
				MX6QDL_PAD_DI0_DISP_CLK__GPIO4_IO16	(PAD__HYS__DIS | PAD__PUS__100K_OHM_PD | PAD__PUE__PULL | PAD__PKE__EN  | PAD__ODE__DIS | PAD__SPEED__MEDIUM2 | PAD__DSE__43_OHM  | PAD__SRE__FAST)		/* LCD1_BKLT_EN */
				MX6QDL_PAD_DI0_PIN3__GPIO4_IO19		(PAD__HYS__DIS | PAD__PUS__100K_OHM_PD | PAD__PUE__PULL | PAD__PKE__EN  | PAD__ODE__DIS | PAD__SPEED__MEDIUM2 | PAD__DSE__43_OHM  | PAD__SRE__FAST)		/* LCD1_VDD_EN */
			>;
		};
	};

	pcie {
		pinctrl_pcie1: pinctrl_pcie1 {
			fsl,pins = <
				MX6QDL_PAD_EIM_A22__GPIO2_IO16		(PAD__HYS__DIS | PAD__PUS__100K_OHM_PD | PAD__PUE__PULL | PAD__PKE__EN  | PAD__ODE__DIS | PAD__SPEED__MEDIUM2 | PAD__DSE__43_OHM  | PAD__SRE__FAST)		/* PCIE reset */
				MX6QDL_PAD_GPIO_18__GPIO7_IO13		(PAD__HYS__DIS | PAD__PUS__100K_OHM_PD | PAD__PUE__PULL | PAD__PKE__EN  | PAD__ODE__DIS | PAD__SPEED__MEDIUM2 | PAD__DSE__43_OHM  | PAD__SRE__FAST)		/* RST_OUTn */
				MX6QDL_PAD_GPIO_19__GPIO4_IO05		(PAD__HYS__DIS | PAD__PUS__100K_OHM_PD | PAD__PUE__PULL | PAD__PKE__EN  | PAD__ODE__DIS | PAD__SPEED__MEDIUM2 | PAD__DSE__43_OHM  | PAD__SRE__FAST)		/* iMX6 P5, SoM P114, SMARC2 GPIO6, Linux GPIO 101, Output to switch PCIe power enable */
			>;
		};
	};

	audmux {
		pinctrl_audmux_2: audmux-2 {
			fsl,pins = <
				MX6QDL_PAD_CSI0_DAT4__AUD3_TXC		(PAD__HYS__EN  | PAD__PUS__100K_OHM_PD | PAD__PUE__PULL | PAD__PKE__EN  | PAD__ODE__DIS | PAD__SPEED__MEDIUM2 | PAD__DSE__43_OHM  | PAD__SRE__SLOW)		/* iMX6 N1, SoM S42, SMARC2 I2S0_CK, Serial data clock */
				MX6QDL_PAD_CSI0_DAT5__AUD3_TXD		(PAD__HYS__EN  | PAD__PUS__100K_OHM_PD | PAD__PUE__KEEP | PAD__PKE__EN  | PAD__ODE__DIS | PAD__SPEED__MEDIUM2 | PAD__DSE__43_OHM  | PAD__SRE__SLOW)		/* iMX6 P2, SoM S40, SMARC2 I2S0_SDOUT, Serial I2S data output to the codec */
				MX6QDL_PAD_CSI0_DAT6__AUD3_TXFS		(PAD__HYS__EN  | PAD__PUS__100K_OHM_PD | PAD__PUE__PULL | PAD__PKE__EN  | PAD__ODE__DIS | PAD__SPEED__MEDIUM2 | PAD__DSE__43_OHM  | PAD__SRE__SLOW)		/* iMX6 N4, SoM S39, SMARC2 I2S0_LRCK, Sample-synchronization signal to the codec(s) */
				MX6QDL_PAD_CSI0_DAT7__AUD3_RXD		(PAD__HYS__EN  | PAD__PUS__100K_OHM_PD | PAD__PUE__PULL | PAD__PKE__EN  | PAD__ODE__DIS | PAD__SPEED__MEDIUM2 | PAD__DSE__43_OHM  | PAD__SRE__SLOW)		/* iMX6 N3, SoM S41, SMARC2 I2S0_SDIN, Serial I2S data inputs from the codec */
				MX6QDL_PAD_CSI0_MCLK__CCM_CLKO1		(PAD__HYS__EN  | PAD__PUS__100K_OHM_PD | PAD__PUE__PULL | PAD__PKE__EN  | PAD__ODE__DIS | PAD__SPEED__MEDIUM2 | PAD__DSE__43_OHM  | PAD__SRE__SLOW)		/* iMX6 P4, SoM S38, SMARC2 AUDIO_MCK, Codec clock supply (24MHz) */
			>;
		};
	};

	max98357a {
		sdmode_en: sdmode-en {
			fsl,pins = <
				MX6QDL_PAD_SD4_DAT5__GPIO2_IO13		(PAD__HYS__DIS | PAD__PUS__100K_OHM_PD | PAD__PUE__PULL | PAD__PKE__EN  | PAD__ODE__DIS | PAD__SPEED__MEDIUM2 | PAD__DSE__43_OHM  | PAD__SRE__FAST)		/* iMX6 C19, SoM P119, SMARC2 GPIO11, SD_MODE */
			>;
		};
	};

	flexcan1 {
		pinctrl_flexcan1_1: flexcan1grp-1 {
			fsl,pins = <
				MX6QDL_PAD_GPIO_8__FLEXCAN1_RX		(PAD__HYS__DIS | PAD__PUS__100K_OHM_PD | PAD__PUE__KEEP | PAD__PKE__DIS | PAD__ODE__DIS | PAD__SPEED__LOW     | PAD__DSE__HIZ     | PAD__SRE__SLOW | IMX_NO_PAD_CTL)
				MX6QDL_PAD_GPIO_7__FLEXCAN1_TX		(PAD__HYS__DIS | PAD__PUS__100K_OHM_PD | PAD__PUE__KEEP | PAD__PKE__DIS | PAD__ODE__DIS | PAD__SPEED__LOW     | PAD__DSE__HIZ     | PAD__SRE__SLOW | IMX_NO_PAD_CTL)
			>;
		};
	};

	flexcan2 {
		pinctrl_flexcan2_1: flexcan2grp-1 {
			fsl,pins = <
				MX6QDL_PAD_KEY_ROW4__FLEXCAN2_RX	(PAD__HYS__DIS | PAD__PUS__100K_OHM_PD | PAD__PUE__KEEP | PAD__PKE__DIS | PAD__ODE__DIS | PAD__SPEED__LOW     | PAD__DSE__HIZ     | PAD__SRE__SLOW | IMX_NO_PAD_CTL)
				MX6QDL_PAD_KEY_COL4__FLEXCAN2_TX	(PAD__HYS__DIS | PAD__PUS__100K_OHM_PD | PAD__PUE__KEEP | PAD__PKE__DIS | PAD__ODE__DIS | PAD__SPEED__LOW     | PAD__DSE__HIZ     | PAD__SRE__SLOW | IMX_NO_PAD_CTL)
			>;
		};
	};

	i2c1 {
		pinctrl_i2c1_1: i2c1grp-1 {
			fsl,pins = <
				MX6QDL_PAD_EIM_D21__I2C1_SCL		(PAD__HYS__EN  | PAD__PUS__100K_OHM_PU | PAD__PUE__PULL | PAD__PKE__EN  | PAD__ODE__EN  | PAD__SPEED__MEDIUM2 | PAD__DSE__43_OHM  | PAD__SRE__FAST | IMX_PAD_SION)
				MX6QDL_PAD_EIM_D28__I2C1_SDA		(PAD__HYS__EN  | PAD__PUS__100K_OHM_PU | PAD__PUE__PULL | PAD__PKE__EN  | PAD__ODE__EN  | PAD__SPEED__MEDIUM2 | PAD__DSE__43_OHM  | PAD__SRE__FAST | IMX_PAD_SION)
			>;
		};

		pinctrl_i2c1_2: i2c1grp-2 {
			fsl,pins = <
				MX6QDL_PAD_CSI0_DAT8__I2C1_SDA		(PAD__HYS__EN  | PAD__PUS__100K_OHM_PU | PAD__PUE__PULL | PAD__PKE__EN  | PAD__ODE__EN  | PAD__SPEED__MEDIUM2 | PAD__DSE__43_OHM  | PAD__SRE__FAST | IMX_PAD_SION)
				MX6QDL_PAD_CSI0_DAT9__I2C1_SCL		(PAD__HYS__EN  | PAD__PUS__100K_OHM_PU | PAD__PUE__PULL | PAD__PKE__EN  | PAD__ODE__EN  | PAD__SPEED__MEDIUM2 | PAD__DSE__43_OHM  | PAD__SRE__FAST | IMX_PAD_SION)
				MX6QDL_PAD_SD4_DAT2__GPIO2_IO10		(PAD__HYS__DIS | PAD__PUS__100K_OHM_PD | PAD__PUE__PULL | PAD__PKE__EN  | PAD__ODE__DIS | PAD__SPEED__MEDIUM2 | PAD__DSE__43_OHM  | PAD__SRE__FAST)		/* iMX6 F17, SoM P116, SMARC2 GPIO8, Linux GPIO 42, PCA9555 interrupt input */
			>;
		};
	};

	i2c2 {
		pinctrl_i2c2_1: i2c2grp-1 {
			fsl,pins = <
				MX6QDL_PAD_EIM_EB2__I2C2_SCL		(PAD__HYS__EN  | PAD__PUS__100K_OHM_PU | PAD__PUE__PULL | PAD__PKE__EN  | PAD__ODE__EN  | PAD__SPEED__MEDIUM2 | PAD__DSE__43_OHM  | PAD__SRE__FAST | IMX_PAD_SION)
				MX6QDL_PAD_EIM_D16__I2C2_SDA		(PAD__HYS__EN  | PAD__PUS__100K_OHM_PU | PAD__PUE__PULL | PAD__PKE__EN  | PAD__ODE__EN  | PAD__SPEED__MEDIUM2 | PAD__DSE__43_OHM  | PAD__SRE__FAST | IMX_PAD_SION)
			>;
		};

		pinctrl_i2c2_2: i2c2grp-2 {
			fsl,pins = <
				MX6QDL_PAD_KEY_COL3__I2C2_SCL		(PAD__HYS__EN  | PAD__PUS__100K_OHM_PU | PAD__PUE__PULL | PAD__PKE__EN  | PAD__ODE__EN  | PAD__SPEED__MEDIUM2 | PAD__DSE__43_OHM  | PAD__SRE__FAST | IMX_PAD_SION)
				MX6QDL_PAD_KEY_ROW3__I2C2_SDA		(PAD__HYS__EN  | PAD__PUS__100K_OHM_PU | PAD__PUE__PULL | PAD__PKE__EN  | PAD__ODE__EN  | PAD__SPEED__MEDIUM2 | PAD__DSE__43_OHM  | PAD__SRE__FAST | IMX_PAD_SION)
			>;
		};

		pinctrl_i2c2_3: i2c2grp-3 {
			fsl,pins = <
				MX6QDL_PAD_EIM_EB2__I2C2_SCL		(PAD__HYS__EN  | PAD__PUS__100K_OHM_PU | PAD__PUE__PULL | PAD__PKE__EN  | PAD__ODE__EN  | PAD__SPEED__MEDIUM2 | PAD__DSE__43_OHM  | PAD__SRE__FAST | IMX_PAD_SION)
				MX6QDL_PAD_KEY_ROW3__I2C2_SDA		(PAD__HYS__EN  | PAD__PUS__100K_OHM_PU | PAD__PUE__PULL | PAD__PKE__EN  | PAD__ODE__EN  | PAD__SPEED__MEDIUM2 | PAD__DSE__43_OHM  | PAD__SRE__FAST | IMX_PAD_SION)
			>;
		};
	};

	i2c3 {
		pinctrl_i2c3: i2c3grp {
			fsl,pins = <
				MX6QDL_PAD_GPIO_5__I2C3_SCL		(PAD__HYS__EN  | PAD__PUS__100K_OHM_PU | PAD__PUE__PULL | PAD__PKE__EN  | PAD__ODE__EN  | PAD__SPEED__MEDIUM2 | PAD__DSE__43_OHM  | PAD__SRE__FAST | IMX_PAD_SION)
				MX6QDL_PAD_GPIO_6__I2C3_SDA		(PAD__HYS__EN  | PAD__PUS__100K_OHM_PU | PAD__PUE__PULL | PAD__PKE__EN  | PAD__ODE__EN  | PAD__SPEED__MEDIUM2 | PAD__DSE__43_OHM  | PAD__SRE__FAST | IMX_PAD_SION)
			>;
		};
	};

	i2c4 {
		pinctrl_pm_i2c_0: pmi2cgrp-1 {
			fsl,pins = <
				MX6QDL_PAD_NANDF_WP_B__I2C4_SCL		(PAD__HYS__EN  | PAD__PUS__100K_OHM_PU | PAD__PUE__PULL | PAD__PKE__EN  | PAD__ODE__EN  | PAD__SPEED__MEDIUM2 | PAD__DSE__43_OHM  | PAD__SRE__FAST | IMX_PAD_SION)
				MX6QDL_PAD_NANDF_CS3__I2C4_SDA		(PAD__HYS__EN  | PAD__PUS__100K_OHM_PU | PAD__PUE__PULL | PAD__PKE__EN  | PAD__ODE__EN  | PAD__SPEED__MEDIUM2 | PAD__DSE__43_OHM  | PAD__SRE__FAST | IMX_PAD_SION)
				MX6QDL_PAD_SD4_DAT4__GPIO2_IO12		(PAD__HYS__DIS | PAD__PUS__100K_OHM_PD | PAD__PUE__PULL | PAD__PKE__EN  | PAD__ODE__DIS | PAD__SPEED__MEDIUM2 | PAD__DSE__43_OHM  | PAD__SRE__FAST)		/* iMX6 E18, SoM P118, SMARC2 GPIO10, Linux GPIO 44, Output to write-protect carrier data EEPROM U12 */
			>;
		};
	};

	lcd_i2c {
		pinctrl_lcd_i2c_1: lcdi2cgrp-1 {
			fsl,pins = <
				MX6QDL_PAD_CSI0_DAT13__GPIO5_IO31	(PAD__HYS__EN  | PAD__PUS__100K_OHM_PU | PAD__PUE__PULL | PAD__PKE__EN  | PAD__ODE__EN  | PAD__SPEED__MEDIUM2 | PAD__DSE__43_OHM  | PAD__SRE__FAST | IMX_PAD_SION)	/* SCL */
				MX6QDL_PAD_CSI0_DAT12__GPIO5_IO30	(PAD__HYS__EN  | PAD__PUS__100K_OHM_PU | PAD__PUE__PULL | PAD__PKE__EN  | PAD__ODE__EN  | PAD__SPEED__MEDIUM2 | PAD__DSE__43_OHM  | PAD__SRE__FAST | IMX_PAD_SION)	/* SDA */
			>;
		};
	};

};

/ {
	msc,dt-version = "2.0";

	regulators {
		compatible = "simple-bus";

		reg_usb_otg_vbus: usb_otg_vbus {
			compatible = "regulator-fixed";
			regulator-name = "usb_otg_vbus";
			regulator-min-microvolt = <5000000>;
			regulator-max-microvolt = <5000000>;
			gpio = <&gpio3 22 0>;
			enable-active-high;
		};

		reg_usb_h1_vbus: usb_h1_vbus {
			compatible = "regulator-fixed";
			regulator-name = "usb_h1_vbus";
			regulator-min-microvolt = <5000000>;
			regulator-max-microvolt = <5000000>;
			regulator-always-on;
		};

		reg_aud_vdda: reg_aud_vdda {
			compatible = "regulator-fixed";
			regulator-name = "VDDA";
			regulator-min-microvolt = <3300000>;
			regulator-max-microvolt = <3300000>;
			regulator-always-on;
		};

		reg_aud_vddio: reg_aud_vddio {
			compatible = "regulator-fixed";
			regulator-name = "VDDIO";
			regulator-min-microvolt = <1800000>;
			regulator-max-microvolt = <1800000>;
			regulator-always-on;
		};

		reg_1p5v: 1p5v {
			compatible = "regulator-fixed";
			regulator-name = "1P5V";
			regulator-min-microvolt = <1500000>;
			regulator-max-microvolt = <1500000>;
			regulator-always-on;
		};

		reg_1p8v: 1p8v {
			compatible = "regulator-fixed";
			regulator-name = "1P8V";
			regulator-min-microvolt = <1800000>;
			regulator-max-microvolt = <1800000>;
			regulator-always-on;
		};

		reg_2p8v: 2p8v {
			compatible = "regulator-fixed";
			regulator-name = "2P8V";
			regulator-min-microvolt = <2800000>;
			regulator-max-microvolt = <2800000>;
			regulator-always-on;
		};

		reg_3p3v: 3p3v {
			compatible = "regulator-fixed";
			regulator-name = "3P3V";
			regulator-min-microvolt = <3300000>;
			regulator-max-microvolt = <3300000>;
			regulator-always-on;
		};

		/* UltiMainboard v4.x PCIE_POWER power switch (U26) */
		reg_pcie_switch: pcie_switch {
			compatible = "regulator-fixed";
			regulator-name = "3v3_pcie";
			regulator-min-microvolt = <3300000>;
			regulator-max-microvolt = <3300000>;
			gpio = <&gpio4 5 0>;		/* PCIE_POWER */
			enable-active-high;
		};

		/* UltiMainboard v4.x VCC5_EXT power switch (U4) */
		reg_vcc5ext: vcc5ext {
			compatible = "regulator-fixed";
			regulator-name = "vcc5_ext";
			regulator-min-microvolt = <5000000>;
			regulator-max-microvolt = <5000000>;
			regulator-always-on;
			gpio = <&pca9555 0 0>;		/* VCC5_EXT_EN */
			enable-active-high;
		};

		/* UltiMainboard v4.x VCC5_BUS power switch (U5) */
		reg_vcc5bus: vcc5bus {
			compatible = "regulator-fixed";
			regulator-name = "vcc5_bus";
			regulator-min-microvolt = <5000000>;
			regulator-max-microvolt = <5000000>;
			regulator-always-on;
			gpio = <&pca9555 2 0>;		/* VCC5_BUS_EN */
			enable-active-high;
		};

		/* UltiMainboard v4.x HDMI_PWR power switch (U29) */
		reg_hdmipwr: hdmipwr {
			compatible = "regulator-fixed";
			regulator-name = "hdmi_pwr";
			regulator-min-microvolt = <5000000>;
			regulator-max-microvolt = <5000000>;
			regulator-always-on;
// TODO: This pin will be first set to output-low and the set high. The glitch this produces is propagated onto hdmi_pwr, upsetting the touch screen controller.
//			gpio = <&pca9555 4 0>;		/* HDMI_PWR_EN */
//			enable-active-high;
//
		};

		/* UltiMainboard v4.x VCC5_PH power switch (U36) */
		reg_vcc5ph: vcc5ph {
			compatible = "regulator-fixed";
			regulator-name = "vcc5_ph";
			regulator-min-microvolt = <5000000>;
			regulator-max-microvolt = <5000000>;
			regulator-always-on;
			gpio = <&pca9555 6 0>;		/* VCC5_PH_EN */
			enable-active-high;
		};
	};

	leds {
		compatible = "gpio-leds";
		pinctrl-names = "default";
		pinctrl-0 = <&pinctrl_leds_1>;

		led1 {
			label = "som:orange:module-led";
			gpios = <&gpio1 25 GPIO_ACTIVE_LOW>;
			linux,default-trigger = "heartbeat";
			default-state = "off";
		};

		led2 {
			label = "::sata-act-led";
			gpios = <&gpio4 8 GPIO_ACTIVE_LOW>;
			linux,default-trigger = "none";
			default-state = "off";
		};

		led3 {
			label = "somdebug:red:debug-led-1";
			gpios = <&gpio2 3 GPIO_ACTIVE_LOW>;
			linux,default-trigger = "none";
			default-state = "off";
		};

		led4 {
			label = "somdebug:yellow:debug-led-2";
			gpios = <&gpio2 4 GPIO_ACTIVE_LOW>;
			linux,default-trigger = "none";
			default-state = "off";
		};

		led5 {
			label = "somdebug:green:debug-led-3";
			gpios = <&gpio2 5 GPIO_ACTIVE_LOW>;
			linux,default-trigger = "none";
			default-state = "off";
		};

		/* UltiMainboard v4.x LED0 (D16) */
		led6 {
			label = "carrier:red:um-led-0";
			gpios = <&gpio3 29 GPIO_ACTIVE_HIGH>;
			linux,default-trigger = "mmc0";
			default-state = "off";
		};

		/* UltiMainboard v4.x LED1 (D15) */
		led7 {
			label = "carrier:red:um-led-1";
			gpios = <&gpio7 11 GPIO_ACTIVE_HIGH>;
			linux,default-trigger = "none";
			default-state = "off";
		};

		/* UltiMainboard v4.x LED2 (D17) */
		led8 {
			label = "carrier:red:um-led-2";
			gpios = <&gpio3 28 GPIO_ACTIVE_HIGH>;
			linux,default-trigger = "none";
			default-state = "off";
		};
	};

	lvds0_bl: lvds0_backlight {
		compatible = "pwm-backlight";
		pwms = <&pwm1 0 1000000>;	/* 1000 Hz */
		brightness-levels = <
			  0  10  20  30  40  50  60  70  80  90
			100 110 120 130 140 150 160 170 180 190
			200 210 220 230 240 250 255
		>;
		default-brightness-level = <26>;
		status = "disabled";
	};

	lvds1_bl: lvds1_backlight {
		compatible = "pwm-backlight";
		pwms = <&pwm2 0 1000000>;	/* 1000 Hz */
		brightness-levels = <
			  0  10  20  30  40  50  60  70  80  90
			100 110 120 130 140 150 160 170 180 190
			200 210 220 230 240 250 255
		>;
		default-brightness-level = <26>;
		status = "disabled";
	};

	pwm_fan {
		compatible = "pwm-backlight";
		pwms = <&pwm3 0 40000>;		/* 25kHz */
		brightness-levels = <
			    0  10  20  30  40  50  60  70
			   80  90 100 110 120 140 150 160
			  170 180 190 200 210 220 230 240
			  250 255>;
		default-brightness-level = <25>;
		status = "okay";
	};

	/* UltiMainboard v4.x Audio DAC/Amplifier (U11) */
	codec: max98357a@0 {
		compatible = "maxim,max98357a";
		pinctrl-names = "default";
		pinctrl-0 = <&sdmode_en>;
		sdmode-gpios = <&gpio2 13 GPIO_ACTIVE_HIGH>;	/* TODO: Change to proper GPIO pin */
		sdmode-delay = <2>;
		#sound-dai-cells = <0>;
		status = "okay";
	};

	sound {
		compatible = "simple-audio-card";
/*		pinctrl-names = "default";
		pinctrl-0 = <&pinctrl_audmux_2>;*/
		simple-audio-card,name = "On-board Audio";
		simple-audio-card,format = "i2s";
		simple-audio-card,widgets = "Speaker", "Speakers";
		simple-audio-card,routing = "Speakers", "Speaker";
		simple-audio-card,bitclock-master = <&cpu_dai>;
		simple-audio-card,frame-master = <&cpu_dai>;
		cpu_dai: simple-audio-card,cpu {
			sound-dai = <&ssi1>;
			system-clock-frequency = <883200>;
			dai-tdm-slot-num = <2>;
			dai-tdm-slot-width = <16>;
		};
		codec_dai: simple-audio-card,codec {
			sound-dai = <&codec>;
		};
	};

	v4l2_cap_0 {
		compatible = "fsl,imx6q-v4l2-capture";
		ipu_id = <0>;
		csi_id = <0>;
		mclk_source = <0>;
		status = "disabled";
	};

	v4l2_out {
		compatible = "fsl,mxc_v4l2_output";
		status = "disabled";
	};

	lcd_i2c: i2c@4 {
		compatible = "i2c-gpio";
		#address-cells = <1>;
		#size-cells = <0>;
		/* i2c-gpio,sda-open-drain; */
		/* i2c-gpio,scl-open-drain; */
		i2c-gpio,delay-us = <2>;	/* ~100 kHz */
	};

	pmu {
		interrupt-affinity = <&cpu0>;
	};
};

&i2c1 {
	pinctrl-names = "default";
	pinctrl-0 = <&pinctrl_i2c1_2>;
	clock-frequency = <100000>;
	status = "okay";

	/* UltiMainboard v4.x GPIO I/O expander (U35) */
	pca9555: pca9555@20 {
		compatible = "nxp,pca9555";
		reg = <0x20>;
/*
		TODO: Extract interrupt GPIO pin from pinctrl_i2c1_2, create pinctrl_pca9555 and put it in there.
		pinctrl-names = "default";
		pinctrl-0 = <&pca9555_pins>;
*/
		interrupt-parent = <&gpio2>;		/* GPIO bank 2 */
		interrupts = <10 IRQ_TYPE_LEVEL_LOW>;	/* GPIO pin 10 */
		gpio-controller;
		#gpio-cells = <2>;
		interrupt-controller;
		#interrupt-cells = <2>;
	};

	/* SoM PMIC */
	pmic: pmic@0x58 {
		reg = <0x58>;
		status = "okay";
	};

	/* SoM board temperature sensor */
	thermal: thermal@0x71 {
		compatible = "ti,tmp103";
		reg = <0x71>;
	};

	/* UltiMainboard v4.x USB hub (U15) */
	usb2512b@2c {
		compatible = "microchip,usb2512b";
		reg = <0x2c>;
		reset-gpios = <&gpio1 0 GPIO_ACTIVE_LOW>;
		string-support;
		manufacturer = "Ultimaker";
		product = "UltiMainboard v4.0 USB hub";
	};
};

&i2c2 {
	pinctrl-names = "default";
	pinctrl-0 = <&pinctrl_i2c2_2>;
	clock-frequency = <100000>;
	status = "okay";

	hdmi_display: hdmi@0x50 {
		compatible = "fsl,imx6-hdmi-i2c";
		reg = <0x50>;
		status = "okay";
	};
};

&i2c3 {
	pinctrl-names = "default";
	pinctrl-0 = <&pinctrl_i2c3>;
	clock-frequency = <100000>;
	status = "okay";

	/* SoM board data EEPROM */
	boarddata@0x50 {
		compatible = "msc,boarddata";
		reg = <0x50>;
		header-offset = <0>;
		content-offset = <16>;
		content-length = <64>;
		product-name-offset = <20>;
		serial-number-offset = <60>;
		variant-key-offset = <52>;
		feature-key-offset = <56>;
		revision-offset = <76>;
	};
};

&i2c4 {
	pinctrl-names = "default";
	pinctrl-0 = <&pinctrl_pm_i2c_0>;
	clock-frequency = <100000>;
	status = "okay";

	/* UltiMainboard v4.x carrier data EEPROM (U12) */
	carrierdata@57 {
		compatible = "atmel,24c32";
		reg = <0x57>;
		pagesize = <32>;
		wp-gpios = <&gpio2 12 0>;
	};
};

&lcd_i2c {
	pinctrl-names = "default";
	pinctrl-0 = <&pinctrl_lcd_i2c_1>;
	gpios =
		<&gpio5 30 0>,	/* sda */
		<&gpio5 31 0>;	/* scl */
	status = "okay";
};

&pmic {
	pinctrl-names = "default";
	pinctrl-0 = <&pinctrl_pmicirq>;
	compatible = "dlg,da9063";
	interrupt-parent = <&gpio1>;
	interrupts = <4 IRQ_TYPE_LEVEL_LOW>;
	status = "okay";

	off-sequence = /bits/ 16 <
	/*	reg	val */
		0x19	0xd4
		0x12	0x04
		0x92	0x0F
		0x88	0x06
		0x10F	0xE2
		0x0F	0x19
		0x10E	0x05
		0x0E	0x01
	>;

	sleep-sequence = /bits/ 16 <
	/*	reg	val */
		0x1B	0x9E
		0x0D	0x20
		0x117	0xC0
		0x0B	0x30
		0x114	0x89
		0x20	0x61
		0x21	0x61
	>;

	wake-sequence = /bits/ 16 <
	/*	reg	val */
		0x117	0xCC
	>;

	on-sequence = /bits/ 16 <
	/*	reg	val */
		0x10F	0xE3
		0x10E	0x04
	>;

	regulators {
		bcore1 {
			regulator-name = "bcore1";
			regulator-always-on = <1>;
			regulator-min-microvolt = <300000>;
			regulator-max-microvolt = <3300000>;
		};

		bcore2 {
			regulator-name = "bcore2";
			regulator-always-on = <1>;
			regulator-min-microvolt = <1420000>;	/* TODO: Check with MSC reference board, as this voltage is increased from 1380mV: [    1.404821] bcore2: Bringing 1380000uV into 1420000-1420000uV */
			regulator-max-microvolt = <1420000>;
		};

		bpro {
			regulator-name = "bpro";
			regulator-always-on = <1>;
			regulator-min-microvolt = <1200000>;
			regulator-max-microvolt = <1200000>;
		};

		bmem {
			regulator-name = "bmem";
			regulator-always-on = <1>;
			regulator-min-microvolt = <1360000>;	/* TODO: Check with MSC reference board, as this voltage is lowered from 1500mV: [    1.420543] bmem: Bringing 1500000uV into 1360000-1360000uV */
			regulator-max-microvolt = <1360000>;
		};

		bperi {
			regulator-name = "bperi";
			regulator-always-on = <1>;
			regulator-min-microvolt = <300000>;
			regulator-max-microvolt = <3300000>;
		};

		ldo2 {
			regulator-name = "ldo2";
			regulator-always-on = <1>;
			regulator-min-microvolt = <300000>;
			regulator-max-microvolt = <1800000>;
		};

		ldo3 {
			regulator-name = "ldo3";
			regulator-always-on = <1>;
			regulator-min-microvolt = <300000>;
			regulator-max-microvolt = <3300000>;
		};

		ldo4 {
			regulator-name = "ldo4";
			regulator-always-on = <1>;
			regulator-min-microvolt = <300000>;
			regulator-max-microvolt = <3300000>;
		};

		ldo5 {
			regulator-name = "ldo5";
			regulator-always-on = <1>;
			regulator-min-microvolt = <300000>;
			regulator-max-microvolt = <3300000>;
		};

		ldo6 {
			regulator-name = "ldo6";
			regulator-always-on = <1>;
			regulator-min-microvolt = <300000>;
			regulator-max-microvolt = <3300000>;
		};

		ldo7 {
			regulator-name = "ldo7";
			regulator-always-on = <1>;
			regulator-min-microvolt = <900000>;	/* TODO: Check with MSC reference board. Was: <300000> (Caused: [    1.437575] ldo7: Bringing 0uV into 300000-300000uV, [    1.443869] ldo7: failed to apply 300000-300000uV constraint(-22)) */
			regulator-max-microvolt = <3300000>;
		};

		ldo8 {
			regulator-name = "ldo8";
			regulator-always-on = <1>;
			regulator-min-microvolt = <900000>;	/* TODO: Check with MSC reference board. Was: <300000> (Caused: [    1.445456] ldo8: failed to apply 300000-300000uV constraint(-22)) */
			regulator-max-microvolt = <3300000>;
		};

		ldo9 {
			regulator-name = "ldo9";
			regulator-always-on = <1>;
			regulator-min-microvolt = <1800000>;
			regulator-max-microvolt = <1800000>;
		};

		ldo10 {
			regulator-name = "ldo10";
			regulator-always-on = <1>;
			regulator-min-microvolt = <900000>;	/* TODO: Check with MSC reference board. Was: <300000> ([    1.448366] ldo10: failed to apply 300000-300000uV constraint(-22)) */
			regulator-max-microvolt = <3300000>;
		};

		ldo11 {
			regulator-name = "ldo11";
			regulator-always-on = <1>;
			regulator-min-microvolt = <300000>;
			regulator-max-microvolt = <3300000>;
		};

		bio {
			regulator-name = "bio";
			regulator-always-on = <1>;
			regulator-min-microvolt = <1800000>;
			regulator-max-microvolt = <1800000>;
		};
	};
};

&audmux {
	status = "okay";

	/* Note: 'ssi1' (node of first SSI) corresponds to '_SSI0' below. */
	ssi1 {
		fsl,audmux-port = <MX31_AUDMUX_PORT1_SSI0>;
		fsl,port-config = <
			0x00000000
			IMX_AUDMUX_V2_PDCR_RXDSEL(MX31_AUDMUX_PORT3_SSI_PINS_3)
		>;
	};

	aud3 {
		fsl,audmux-port = <MX31_AUDMUX_PORT3_SSI_PINS_3>;
		fsl,port-config = <
			(IMX_AUDMUX_V2_PTCR_TFSDIR |
			 IMX_AUDMUX_V2_PTCR_TFSEL(MX31_AUDMUX_PORT1_SSI0) |
			 IMX_AUDMUX_V2_PTCR_TCLKDIR |
			 IMX_AUDMUX_V2_PTCR_TCSEL(MX31_AUDMUX_PORT1_SSI0))
			 IMX_AUDMUX_V2_PDCR_RXDSEL(MX31_AUDMUX_PORT1_SSI0)
			>;
	};
};

&ssi1 {
	fsl,mode = "i2s-master";
	assigned-clocks = <&clks IMX6QDL_CLK_SSI1_SEL>, <&clks IMX6QDL_CLK_SSI1>;
	assigned-clock-parents = <&clks IMX6QDL_CLK_PLL4_AUDIO_DIV>;
	assigned-clock-rates = <0>, <49152000>;		/* 48.0kHz on SSI1 clock */
	status = "okay";
};

&gpc {
	fsl,cpu_pupscr_sw2iso = <0xf>;
	fsl,cpu_pupscr_sw = <0xf>;
	fsl,cpu_pdnscr_iso2sw = <0x1>;
	fsl,cpu_pdnscr_iso = <0x1>;
	fsl,ldo-bypass = <0>;	/* use ldo-bypass, u-boot will check it and configure */
	fsl,wdog-reset = <1>;	/* watchdog select of reset source */
};
&vpu {
	iramsize = <0>;
	status = "okay";
};
&pwm1 {
	pinctrl-names = "default";
	pinctrl-0 = <&pinctrl_pwm1_2>;
	status = "disabled";
};

&pwm2 {
	pinctrl-names = "default";
	pinctrl-0 = <&pinctrl_pwm2_2>;
	status = "disabled";
};
#ifndef IMX6DL_ULTIMAKER
&pwm3 {
	pinctrl-names = "default";
	pinctrl-0 = <&pinctrl_pwm3_2>;
	status = "okay";
};
#endif
&can1 {
	pinctrl-names = "default";
	pinctrl-0 = <&pinctrl_flexcan1_1>;
#ifdef IMX6DL_ULTIMAKER
	status = "disabled"; /* clashes with our designs for GPIO 7 and 8 */
#else
	status = "okay";
#endif
};

&can2 {
	pinctrl-names = "default";
	pinctrl-0 = <&pinctrl_flexcan2_1>;
	status = "okay";
};

&gpmi {
	status = "disabled";
};

&fec {
	pinctrl-names = "default";
	pinctrl-0 = <&pinctrl_sm2_enet_1>;
	phy-mode = "rgmii";
	status = "okay";
};

&ecspi1 {
	pinctrl-names = "default";
	pinctrl-0 = <&pinctrl_ecspi1_1>;
	fsl,spi-num-chipselects = <1>;
	cs-gpios = <&gpio2 30 0>;
	status = "okay";

	module_flash: m25@0 {
		#address-cells = <1>;
		#size-cells = <1>;
		compatible = "gd25lq64";
		spi-max-frequency = <50000000>;
		reg = <0>;

		partition@0 {
			label = "SPL";
			reg = <0x0 0x20000>;
		};
		partition@20000 {
			label = "env";
			reg = <0x20000 0x20000>;
		};
		partition@40000 {
			label = "uboot";
			reg = <0x40000 0x80000>;
		};
		partition@c0000 {
			label = "user";
			reg = <0xc0000 0x0>;
		};
	};
};

&ecspi2 {
	pinctrl-names = "default";
	pinctrl-0 = <&pinctrl_ecspi2_1>;
	fsl,spi-num-chipselects = <2>;
	cs-gpios = <&gpio5 12 0>, <&gpio5 9 0>;
	status = "okay";

	test_flash2_0: m25@0 {
		#address-cells = <1>;
		#size-cells = <1>;
		compatible = "w25q64fw";
		spi-max-frequency = <20000000>;
		reg = <0>;

		partition@0 {
			label = "space2_0";
			reg = <0x0 0x800000>;
		};
	};

	test_flash2_1: m25@1 {
		#address-cells = <1>;
		#size-cells = <1>;
		compatible = "w25q64fw";
		spi-max-frequency = <20000000>;
		reg = <1>;

		partition@0 {
			label = "space2_1";
			reg = <0x0 0x800000>;
		};
	};
};

#ifdef ULTIMAKER_SPI_TEST
&ecspi3 {
	pinctrl-names = "default";
	pinctrl-0 = <&pinctrl_ecspi3_1>;
	fsl,spi-num-chipselects = <2>;
	cs-gpios = <&gpio4 24 0>, <&gpio4 25 0>;
	status = "okay";

	test_flash3_0: m25@0 {
		#address-cells = <1>;
		#size-cells = <1>;
		compatible = "w25q64fw";
		spi-max-frequency = <20000000>;
		reg = <0>;

		partition@0 {
			label = "space3_0";
			reg = <0x0 0x800000>;
		};
	};

#ifdef IMX6DL_ULTIMAKER
	/*
	 * user space SPI interface (want kernel to create /dev/spi2.1)
	 */
	spidev: spidev@1 {
		status = "okay";
		compatible = "linux,spidev";
		spi-max-frequency = <50000000>;
		reg = <1>;
	};
#else
	test_flash3_1: m25@1 {
		#address-cells = <1>;
		#size-cells = <1>;
		compatible = "w25q64fw";
		spi-max-frequency = <20000000>;
		reg = <1>;

		partition@0 {
			label = "space3_1";
			reg = <0x0 0x800000>;
		};
	};
#endif
};
#endif

&usbh1 {
	pinctrl-names = "default";
	pinctrl-0 = <&pinctrl_usbhost>;
	pinctrl-assert-gpios = <&gpio4 27 GPIO_ACTIVE_HIGH>;
	vbus-supply = <&reg_usb_h1_vbus>;
	status = "okay";
};

&usbotg {
	pinctrl-names = "default";
	pinctrl-0 = <&pinctrl_usbotg>;
	vbus-supply = <&reg_usb_otg_vbus>;
	disable-over-current;
	status = "okay";
};

&usdhc1 {
	pinctrl-names = "default";
	pinctrl-0 = <&pinctrl_usdhc1_1>;
	cd-gpios = <&gpio1 27 GPIO_ACTIVE_LOW>;
	no-1-8-v;
	status = "okay";
};

&usdhc2 {
	pinctrl-names = "default";
	pinctrl-0 = <&pinctrl_usdhc2_2>;
	cd-gpios = <&gpio1 29 GPIO_ACTIVE_LOW>;
	no-1-8-v;
	status = "okay";
};

&usdhc3 {
	pinctrl-names = "default";
	pinctrl-0 = <&pinctrl_usdhc3_1_100mhz_120Ohm>;
	bus-width = <8>;
	non-removable;
	status = "okay";
};

&uart1 {
	pinctrl-names = "default";
	pinctrl-0 = <&pinctrl_uart1>;
	fsl,uart-has-rtscts;
	status = "okay";
};

&uart2 {
	pinctrl-names = "default";
	pinctrl-0 = <&pinctrl_uart2>;
	status = "okay";
};

&uart3 {
	pinctrl-names = "default";
	pinctrl-0 = <&pinctrl_uart3>;
	fsl,uart-has-rtscts;
	status = "okay";
};

&uart4 {
	pinctrl-names = "default";
	pinctrl-0 = <&pinctrl_uart4>;
	status = "okay";
};

&uart5 {
	pinctrl-names = "default";
	pinctrl-0 = <&pinctrl_uart5>;
	status = "okay";
};

&audmux {
	pinctrl-names = "default";
	pinctrl-0 = <&pinctrl_audmux_2>;
	status = "okay";
};

&ssi1 {
	fsl,mode = "i2s-slave";
	status = "okay";
};

&pcie {
	pinctrl-names = "default";
	pinctrl-0 = <&pinctrl_pcie1>;
	reset-gpio = <&gpio2 16 0>;
	pinctrl-assert-gpios = <&gpio7 13 GPIO_ACTIVE_HIGH>;
	vpcie-supply = <&reg_pcie_switch>;
	status = "okay";
};
#if 0
&hdmi_core {
	ipu_id = <0>;
	disp_id = <1>;
	status = "disabled";
};

&hdmi_video {
	fsl,phy_reg_vlev = <0x0294>;
	fsl,phy_reg_cksymtx = <0x800d>;
	status = "disabled";
};
#endif
&mipi_csi {
	ipu_id = <0>;
	csi_id = <0>;
	v_channel = <0>;
	lanes = <2>;
	status = "disabled";
};

&ldb {
	pinctrl-names = "default";
	pinctrl-0 = <&pinctrl_lvds0_blen>;
	status = "disabled";

	lvds-channel@0 {
		fsl,data-mapping = "spwg";
		fsl,data-width = <24>;
		primary;
		status = "disabled";
		blon-delay-ms = <150>;
		bloff-delay-ms = <100>;
		blen-gpio = <&gpio6 31 0>;
		ppon-delay-ms = <150>;
		ppoff-delay-ms = <50>;
		ppen-gpio = <&gpio6 15 0>;
		lvdson-delay-ms = <30>;

		display-timings {
			native-mode = <&lvds0_timings>;
			lvds0_timings: timing@0 {
				clock-frequency = <35000000>;
				hactive = <800>;
				vactive = <600>;
				hback-porch = <118>;
				hfront-porch = <118>;
				vback-porch = <9>;
				vfront-porch = <9>;
				hsync-len = <40>;
				vsync-len = <10>;
			};
		};
	};

	lvds-channel@1 {
		fsl,data-mapping = "spwg";
		fsl,data-width = <24>;
		status = "disabled";

		blon-delay-ms = <20>;
		bloff-delay-ms = <50>;
		blen-gpio = <&gpio4 16 0>;
		ppon-delay-ms = <20>;
		ppoff-delay-ms = <10>;
		ppen-gpio = <&gpio4 19 0>;
		lvdson-delay-ms = <30>;

		display-timings {
			native-mode = <&lvds1_timings>;
			lvds1_timings: timing@1 {
				clock-frequency = <35000000>;
				hactive = <800>;
				vactive = <600>;
				hback-porch = <118>;
				hfront-porch = <118>;
				vback-porch = <9>;
				vfront-porch = <9>;
				hsync-len = <40>;
				vsync-len = <10>;
			};
		};
	};
};

&iomuxc {
	pinctrl-names = "default";
	pinctrl-0 = <&pinctrl_hog_1>;

	hog {
		pinctrl_hog_1: hoggrp-1 {
			fsl,pins = <
#ifdef IMX6DL_ULTIMAKER
				MX6QDL_PAD_SD4_DAT1__GPIO2_IO09		(PAD__HYS__DIS | PAD__PUS__100K_OHM_PD | PAD__PUE__PULL | PAD__PKE__EN  | PAD__ODE__DIS | PAD__SPEED__MEDIUM2 | PAD__DSE__43_OHM  | PAD__SRE__FAST)		/* ATMEL nRST - NOT PWM3! */
#endif
#ifndef ULTIMAKER_SPI_TEST
				MX6QDL_PAD_DISP0_DAT2__GPIO4_IO23	(PAD__HYS__DIS | PAD__PUS__100K_OHM_PD | PAD__PUE__PULL | PAD__PKE__EN  | PAD__ODE__DIS | PAD__SPEED__MEDIUM2 | PAD__DSE__43_OHM  | PAD__SRE__FAST)
				MX6QDL_PAD_DISP0_DAT1__GPIO4_IO22	(PAD__HYS__DIS | PAD__PUS__100K_OHM_PD | PAD__PUE__PULL | PAD__PKE__EN  | PAD__ODE__DIS | PAD__SPEED__MEDIUM2 | PAD__DSE__43_OHM  | PAD__SRE__FAST)
				MX6QDL_PAD_DISP0_DAT0__GPIO4_IO21	(PAD__HYS__DIS | PAD__PUS__100K_OHM_PD | PAD__PUE__PULL | PAD__PKE__EN  | PAD__ODE__DIS | PAD__SPEED__MEDIUM2 | PAD__DSE__43_OHM  | PAD__SRE__FAST)
#endif
				MX6QDL_PAD_EIM_LBA__GPIO2_IO27		(PAD__HYS__DIS | PAD__PUS__100K_OHM_PD | PAD__PUE__PULL | PAD__PKE__EN  | PAD__ODE__DIS | PAD__SPEED__MEDIUM2 | PAD__DSE__43_OHM  | PAD__SRE__FAST)
				MX6QDL_PAD_EIM_RW__GPIO2_IO26		(PAD__HYS__DIS | PAD__PUS__100K_OHM_PD | PAD__PUE__PULL | PAD__PKE__EN  | PAD__ODE__DIS | PAD__SPEED__MEDIUM2 | PAD__DSE__43_OHM  | PAD__SRE__FAST)
				MX6QDL_PAD_EIM_A16__GPIO2_IO22		(PAD__HYS__DIS | PAD__PUS__100K_OHM_PD | PAD__PUE__PULL | PAD__PKE__EN  | PAD__ODE__DIS | PAD__SPEED__MEDIUM2 | PAD__DSE__43_OHM  | PAD__SRE__FAST)
				MX6QDL_PAD_EIM_A17__GPIO2_IO21		(PAD__HYS__DIS | PAD__PUS__100K_OHM_PD | PAD__PUE__PULL | PAD__PKE__EN  | PAD__ODE__DIS | PAD__SPEED__MEDIUM2 | PAD__DSE__43_OHM  | PAD__SRE__FAST)
				MX6QDL_PAD_EIM_A18__GPIO2_IO20		(PAD__HYS__DIS | PAD__PUS__100K_OHM_PD | PAD__PUE__PULL | PAD__PKE__EN  | PAD__ODE__DIS | PAD__SPEED__MEDIUM2 | PAD__DSE__43_OHM  | PAD__SRE__FAST)
				MX6QDL_PAD_EIM_A19__GPIO2_IO19		(PAD__HYS__DIS | PAD__PUS__100K_OHM_PD | PAD__PUE__PULL | PAD__PKE__EN  | PAD__ODE__DIS | PAD__SPEED__MEDIUM2 | PAD__DSE__43_OHM  | PAD__SRE__FAST)
				MX6QDL_PAD_EIM_A20__GPIO2_IO18		(PAD__HYS__DIS | PAD__PUS__100K_OHM_PD | PAD__PUE__PULL | PAD__PKE__EN  | PAD__ODE__DIS | PAD__SPEED__MEDIUM2 | PAD__DSE__43_OHM  | PAD__SRE__FAST)
				MX6QDL_PAD_EIM_A21__GPIO2_IO17		(PAD__HYS__DIS | PAD__PUS__100K_OHM_PD | PAD__PUE__PULL | PAD__PKE__EN  | PAD__ODE__DIS | PAD__SPEED__MEDIUM2 | PAD__DSE__43_OHM  | PAD__SRE__FAST)
				MX6QDL_PAD_EIM_A23__GPIO6_IO06		(PAD__HYS__DIS | PAD__PUS__100K_OHM_PD | PAD__PUE__PULL | PAD__PKE__EN  | PAD__ODE__DIS | PAD__SPEED__MEDIUM2 | PAD__DSE__43_OHM  | PAD__SRE__FAST)
				MX6QDL_PAD_EIM_A24__GPIO5_IO04		(PAD__HYS__DIS | PAD__PUS__100K_OHM_PD | PAD__PUE__PULL | PAD__PKE__EN  | PAD__ODE__DIS | PAD__SPEED__MEDIUM2 | PAD__DSE__43_OHM  | PAD__SRE__FAST)
				MX6QDL_PAD_EIM_A25__GPIO5_IO02		(PAD__HYS__DIS | PAD__PUS__100K_OHM_PD | PAD__PUE__PULL | PAD__PKE__EN  | PAD__ODE__DIS | PAD__SPEED__MEDIUM2 | PAD__DSE__43_OHM  | PAD__SRE__FAST)		/* TPM_DAVINTn */
				MX6QDL_PAD_EIM_EB3__GPIO2_IO31		(PAD__HYS__DIS | PAD__PUS__100K_OHM_PD | PAD__PUE__PULL | PAD__PKE__EN  | PAD__ODE__DIS | PAD__SPEED__MEDIUM2 | PAD__DSE__43_OHM  | PAD__SRE__FAST)
				MX6QDL_PAD_EIM_WAIT__GPIO5_IO00		(PAD__HYS__DIS | PAD__PUS__100K_OHM_PD | PAD__PUE__PULL | PAD__PKE__EN  | PAD__ODE__DIS | PAD__SPEED__MEDIUM2 | PAD__DSE__43_OHM  | PAD__SRE__FAST)
				MX6QDL_PAD_EIM_EB1__GPIO2_IO29		(PAD__HYS__DIS | PAD__PUS__100K_OHM_PD | PAD__PUE__PULL | PAD__PKE__EN  | PAD__ODE__DIS | PAD__SPEED__MEDIUM2 | PAD__DSE__43_OHM  | PAD__SRE__FAST)
				MX6QDL_PAD_EIM_DA0__GPIO3_IO00		(PAD__HYS__DIS | PAD__PUS__100K_OHM_PD | PAD__PUE__PULL | PAD__PKE__EN  | PAD__ODE__DIS | PAD__SPEED__MEDIUM2 | PAD__DSE__43_OHM  | PAD__SRE__FAST)
				MX6QDL_PAD_EIM_DA1__GPIO3_IO01		(PAD__HYS__DIS | PAD__PUS__100K_OHM_PD | PAD__PUE__PULL | PAD__PKE__EN  | PAD__ODE__DIS | PAD__SPEED__MEDIUM2 | PAD__DSE__43_OHM  | PAD__SRE__FAST)
				MX6QDL_PAD_EIM_DA2__GPIO3_IO02		(PAD__HYS__DIS | PAD__PUS__100K_OHM_PD | PAD__PUE__PULL | PAD__PKE__EN  | PAD__ODE__DIS | PAD__SPEED__MEDIUM2 | PAD__DSE__43_OHM  | PAD__SRE__FAST)
				MX6QDL_PAD_EIM_DA3__GPIO3_IO03		(PAD__HYS__DIS | PAD__PUS__100K_OHM_PD | PAD__PUE__PULL | PAD__PKE__EN  | PAD__ODE__DIS | PAD__SPEED__MEDIUM2 | PAD__DSE__43_OHM  | PAD__SRE__FAST)
				MX6QDL_PAD_EIM_DA4__GPIO3_IO04		(PAD__HYS__DIS | PAD__PUS__100K_OHM_PD | PAD__PUE__PULL | PAD__PKE__EN  | PAD__ODE__DIS | PAD__SPEED__MEDIUM2 | PAD__DSE__43_OHM  | PAD__SRE__FAST)
				MX6QDL_PAD_EIM_DA5__GPIO3_IO05		(PAD__HYS__DIS | PAD__PUS__100K_OHM_PD | PAD__PUE__PULL | PAD__PKE__EN  | PAD__ODE__DIS | PAD__SPEED__MEDIUM2 | PAD__DSE__43_OHM  | PAD__SRE__FAST)
				MX6QDL_PAD_EIM_DA6__GPIO3_IO06		(PAD__HYS__DIS | PAD__PUS__100K_OHM_PD | PAD__PUE__PULL | PAD__PKE__EN  | PAD__ODE__DIS | PAD__SPEED__MEDIUM2 | PAD__DSE__43_OHM  | PAD__SRE__FAST)
				MX6QDL_PAD_EIM_DA7__GPIO3_IO07		(PAD__HYS__DIS | PAD__PUS__100K_OHM_PD | PAD__PUE__PULL | PAD__PKE__EN  | PAD__ODE__DIS | PAD__SPEED__MEDIUM2 | PAD__DSE__43_OHM  | PAD__SRE__FAST)
				MX6QDL_PAD_EIM_DA8__GPIO3_IO08		(PAD__HYS__DIS | PAD__PUS__100K_OHM_PD | PAD__PUE__PULL | PAD__PKE__EN  | PAD__ODE__DIS | PAD__SPEED__MEDIUM2 | PAD__DSE__43_OHM  | PAD__SRE__FAST)
				MX6QDL_PAD_EIM_DA10__GPIO3_IO10		(PAD__HYS__DIS | PAD__PUS__100K_OHM_PD | PAD__PUE__PULL | PAD__PKE__EN  | PAD__ODE__DIS | PAD__SPEED__MEDIUM2 | PAD__DSE__43_OHM  | PAD__SRE__FAST)
				MX6QDL_PAD_EIM_DA11__GPIO3_IO11		(PAD__HYS__DIS | PAD__PUS__100K_OHM_PD | PAD__PUE__PULL | PAD__PKE__EN  | PAD__ODE__DIS | PAD__SPEED__MEDIUM2 | PAD__DSE__43_OHM  | PAD__SRE__FAST)
				MX6QDL_PAD_EIM_DA12__GPIO3_IO12		(PAD__HYS__DIS | PAD__PUS__100K_OHM_PD | PAD__PUE__PULL | PAD__PKE__EN  | PAD__ODE__DIS | PAD__SPEED__MEDIUM2 | PAD__DSE__43_OHM  | PAD__SRE__FAST)
				MX6QDL_PAD_EIM_DA13__GPIO3_IO13		(PAD__HYS__DIS | PAD__PUS__100K_OHM_PD | PAD__PUE__PULL | PAD__PKE__EN  | PAD__ODE__DIS | PAD__SPEED__MEDIUM2 | PAD__DSE__43_OHM  | PAD__SRE__FAST)
				MX6QDL_PAD_EIM_DA14__GPIO3_IO14		(PAD__HYS__DIS | PAD__PUS__100K_OHM_PD | PAD__PUE__PULL | PAD__PKE__EN  | PAD__ODE__DIS | PAD__SPEED__MEDIUM2 | PAD__DSE__43_OHM  | PAD__SRE__FAST)
				MX6QDL_PAD_EIM_DA15__GPIO3_IO15		(PAD__HYS__DIS | PAD__PUS__100K_OHM_PD | PAD__PUE__PULL | PAD__PKE__EN  | PAD__ODE__DIS | PAD__SPEED__MEDIUM2 | PAD__DSE__43_OHM  | PAD__SRE__FAST)
				MX6QDL_PAD_GPIO_17__GPIO7_IO12		(PAD__HYS__DIS | PAD__PUS__100K_OHM_PD | PAD__PUE__PULL | PAD__PKE__EN  | PAD__ODE__DIS | PAD__SPEED__MEDIUM2 | PAD__DSE__43_OHM  | PAD__SRE__FAST)		/* SMARC2 GPIO3 */
				MX6QDL_PAD_NANDF_CS0__GPIO6_IO11	(PAD__HYS__DIS | PAD__PUS__100K_OHM_PD | PAD__PUE__PULL | PAD__PKE__EN  | PAD__ODE__DIS | PAD__SPEED__MEDIUM2 | PAD__DSE__43_OHM  | PAD__SRE__FAST)
				MX6QDL_PAD_NANDF_ALE__GPIO6_IO08	(PAD__HYS__DIS | PAD__PUS__100K_OHM_PD | PAD__PUE__PULL | PAD__PKE__EN  | PAD__ODE__DIS | PAD__SPEED__MEDIUM2 | PAD__DSE__43_OHM  | PAD__SRE__FAST)		/* HW_CONFIG0 */
				MX6QDL_PAD_NANDF_CLE__GPIO6_IO07	(PAD__HYS__DIS | PAD__PUS__100K_OHM_PD | PAD__PUE__PULL | PAD__PKE__EN  | PAD__ODE__DIS | PAD__SPEED__MEDIUM2 | PAD__DSE__43_OHM  | PAD__SRE__FAST)		/* HW_CONFIG1 */
				MX6QDL_PAD_NANDF_RB0__GPIO6_IO10	(PAD__HYS__DIS | PAD__PUS__100K_OHM_PD | PAD__PUE__PULL | PAD__PKE__EN  | PAD__ODE__DIS | PAD__SPEED__MEDIUM2 | PAD__DSE__43_OHM  | PAD__SRE__FAST)		/* HW_CONFIG2 */
				MX6QDL_PAD_NANDF_D0__GPIO2_IO00		(PAD__HYS__DIS | PAD__PUS__100K_OHM_PD | PAD__PUE__PULL | PAD__PKE__EN  | PAD__ODE__DIS | PAD__SPEED__MEDIUM2 | PAD__DSE__43_OHM  | PAD__SRE__FAST)		/* BOOT_SEL0n */
				MX6QDL_PAD_NANDF_D1__GPIO2_IO01		(PAD__HYS__DIS | PAD__PUS__100K_OHM_PD | PAD__PUE__PULL | PAD__PKE__EN  | PAD__ODE__DIS | PAD__SPEED__MEDIUM2 | PAD__DSE__43_OHM  | PAD__SRE__FAST)		/* BOOT_SEL1n */
				MX6QDL_PAD_NANDF_D2__GPIO2_IO02		(PAD__HYS__DIS | PAD__PUS__100K_OHM_PD | PAD__PUE__PULL | PAD__PKE__EN  | PAD__ODE__DIS | PAD__SPEED__MEDIUM2 | PAD__DSE__43_OHM  | PAD__SRE__FAST)		/* BOOT_SEL2n */
				MX6QDL_PAD_NANDF_D6__GPIO2_IO06		(PAD__HYS__DIS | PAD__PUS__100K_OHM_PD | PAD__PUE__PULL | PAD__PKE__EN  | PAD__ODE__DIS | PAD__SPEED__MEDIUM2 | PAD__DSE__43_OHM  | PAD__SRE__FAST)		/* DDR_CONFIG0*/
				MX6QDL_PAD_NANDF_D7__GPIO2_IO07		(PAD__HYS__DIS | PAD__PUS__100K_OHM_PD | PAD__PUE__PULL | PAD__PKE__EN  | PAD__ODE__DIS | PAD__SPEED__MEDIUM2 | PAD__DSE__43_OHM  | PAD__SRE__FAST)		/* DDR_CONFIG1*/
				MX6QDL_PAD_SD4_CLK__GPIO7_IO10		(PAD__HYS__DIS | PAD__PUS__100K_OHM_PD | PAD__PUE__PULL | PAD__PKE__EN  | PAD__ODE__DIS | PAD__SPEED__MEDIUM2 | PAD__DSE__43_OHM  | PAD__SRE__FAST)		/* DDR_CONFIG2*/
				MX6QDL_PAD_SD4_CMD__GPIO7_IO09		(PAD__HYS__DIS | PAD__PUS__100K_OHM_PD | PAD__PUE__PULL | PAD__PKE__EN  | PAD__ODE__DIS | PAD__SPEED__MEDIUM2 | PAD__DSE__43_OHM  | PAD__SRE__FAST)		/* DDR_CONFIG3*/
				MX6QDL_PAD_SD4_DAT0__GPIO2_IO08		(PAD__HYS__DIS | PAD__PUS__100K_OHM_PD | PAD__PUE__PULL | PAD__PKE__EN  | PAD__ODE__DIS | PAD__SPEED__MEDIUM2 | PAD__DSE__43_OHM  | PAD__SRE__FAST)		/* SMARC2 GPIO4 */
				MX6QDL_PAD_SD4_DAT3__GPIO2_IO11		(PAD__HYS__DIS | PAD__PUS__100K_OHM_PD | PAD__PUE__PULL | PAD__PKE__EN  | PAD__ODE__DIS | PAD__SPEED__MEDIUM2 | PAD__DSE__43_OHM  | PAD__SRE__FAST)		/* SMARC2 GPIO9 */
				MX6QDL_PAD_SD4_DAT6__GPIO2_IO14		(PAD__HYS__DIS | PAD__PUS__100K_OHM_PD | PAD__PUE__PULL | PAD__PKE__EN  | PAD__ODE__DIS | PAD__SPEED__MEDIUM2 | PAD__DSE__43_OHM  | PAD__SRE__FAST)		/* SMARC2 GPIO7 */
				MX6QDL_PAD_CSI0_DAT16__GPIO6_IO02	(PAD__HYS__DIS | PAD__PUS__100K_OHM_PD | PAD__PUE__PULL | PAD__PKE__EN  | PAD__ODE__DIS | PAD__SPEED__MEDIUM2 | PAD__DSE__43_OHM  | PAD__SRE__FAST)
				MX6QDL_PAD_CSI0_DAT17__GPIO6_IO03	(PAD__HYS__DIS | PAD__PUS__100K_OHM_PD | PAD__PUE__PULL | PAD__PKE__EN  | PAD__ODE__DIS | PAD__SPEED__MEDIUM2 | PAD__DSE__43_OHM  | PAD__SRE__FAST)
				MX6QDL_PAD_CSI0_DAT18__GPIO6_IO04	(PAD__HYS__DIS | PAD__PUS__100K_OHM_PD | PAD__PUE__PULL | PAD__PKE__EN  | PAD__ODE__DIS | PAD__SPEED__MEDIUM2 | PAD__DSE__43_OHM  | PAD__SRE__FAST)
				MX6QDL_PAD_CSI0_DAT19__GPIO6_IO05	(PAD__HYS__DIS | PAD__PUS__100K_OHM_PD | PAD__PUE__PULL | PAD__PKE__EN  | PAD__ODE__DIS | PAD__SPEED__MEDIUM2 | PAD__DSE__43_OHM  | PAD__SRE__FAST)
				MX6QDL_PAD_DI0_PIN2__GPIO4_IO18		(PAD__HYS__DIS | PAD__PUS__100K_OHM_PD | PAD__PUE__PULL | PAD__PKE__EN  | PAD__ODE__DIS | PAD__SPEED__MEDIUM2 | PAD__DSE__43_OHM  | PAD__SRE__FAST)
				MX6QDL_PAD_DI0_PIN4__GPIO4_IO20		(PAD__HYS__DIS | PAD__PUS__100K_OHM_PD | PAD__PUE__PULL | PAD__PKE__EN  | PAD__ODE__DIS | PAD__SPEED__MEDIUM2 | PAD__DSE__43_OHM  | PAD__SRE__FAST)
				MX6QDL_PAD_DISP0_DAT7__GPIO4_IO28	(PAD__HYS__DIS | PAD__PUS__100K_OHM_PD | PAD__PUE__PULL | PAD__PKE__EN  | PAD__ODE__DIS | PAD__SPEED__MEDIUM2 | PAD__DSE__43_OHM  | PAD__SRE__FAST)
				MX6QDL_PAD_DISP0_DAT8__GPIO4_IO29	(PAD__HYS__DIS | PAD__PUS__100K_OHM_PD | PAD__PUE__PULL | PAD__PKE__EN  | PAD__ODE__DIS | PAD__SPEED__MEDIUM2 | PAD__DSE__43_OHM  | PAD__SRE__FAST)
				MX6QDL_PAD_DISP0_DAT10__GPIO4_IO31	(PAD__HYS__DIS | PAD__PUS__100K_OHM_PD | PAD__PUE__PULL | PAD__PKE__EN  | PAD__ODE__DIS | PAD__SPEED__MEDIUM2 | PAD__DSE__43_OHM  | PAD__SRE__FAST)
				MX6QDL_PAD_DISP0_DAT11__GPIO5_IO05	(PAD__HYS__DIS | PAD__PUS__100K_OHM_PD | PAD__PUE__PULL | PAD__PKE__EN  | PAD__ODE__DIS | PAD__SPEED__MEDIUM2 | PAD__DSE__43_OHM  | PAD__SRE__FAST)
				MX6QDL_PAD_DISP0_DAT12__GPIO5_IO06	(PAD__HYS__DIS | PAD__PUS__100K_OHM_PD | PAD__PUE__PULL | PAD__PKE__EN  | PAD__ODE__DIS | PAD__SPEED__MEDIUM2 | PAD__DSE__43_OHM  | PAD__SRE__FAST)
				MX6QDL_PAD_DISP0_DAT13__GPIO5_IO07	(PAD__HYS__DIS | PAD__PUS__100K_OHM_PD | PAD__PUE__PULL | PAD__PKE__EN  | PAD__ODE__DIS | PAD__SPEED__MEDIUM2 | PAD__DSE__43_OHM  | PAD__SRE__FAST)
				MX6QDL_PAD_DISP0_DAT14__GPIO5_IO08	(PAD__HYS__DIS | PAD__PUS__100K_OHM_PD | PAD__PUE__PULL | PAD__PKE__EN  | PAD__ODE__DIS | PAD__SPEED__MEDIUM2 | PAD__DSE__43_OHM  | PAD__SRE__FAST)
				MX6QDL_PAD_DISP0_DAT16__GPIO5_IO10	(PAD__HYS__DIS | PAD__PUS__100K_OHM_PD | PAD__PUE__PULL | PAD__PKE__EN  | PAD__ODE__DIS | PAD__SPEED__MEDIUM2 | PAD__DSE__43_OHM  | PAD__SRE__FAST)
				MX6QDL_PAD_DISP0_DAT17__GPIO5_IO11	(PAD__HYS__DIS | PAD__PUS__100K_OHM_PD | PAD__PUE__PULL | PAD__PKE__EN  | PAD__ODE__DIS | PAD__SPEED__MEDIUM2 | PAD__DSE__43_OHM  | PAD__SRE__FAST)
				MX6QDL_PAD_DISP0_DAT19__GPIO5_IO13	(PAD__HYS__DIS | PAD__PUS__100K_OHM_PD | PAD__PUE__PULL | PAD__PKE__EN  | PAD__ODE__DIS | PAD__SPEED__MEDIUM2 | PAD__DSE__43_OHM  | PAD__SRE__FAST)
				MX6QDL_PAD_DISP0_DAT20__GPIO5_IO14	(PAD__HYS__DIS | PAD__PUS__100K_OHM_PD | PAD__PUE__PULL | PAD__PKE__EN  | PAD__ODE__DIS | PAD__SPEED__MEDIUM2 | PAD__DSE__43_OHM  | PAD__SRE__FAST)
				MX6QDL_PAD_DISP0_DAT21__GPIO5_IO15	(PAD__HYS__DIS | PAD__PUS__100K_OHM_PD | PAD__PUE__PULL | PAD__PKE__EN  | PAD__ODE__DIS | PAD__SPEED__MEDIUM2 | PAD__DSE__43_OHM  | PAD__SRE__FAST)
				MX6QDL_PAD_DISP0_DAT22__GPIO5_IO16	(PAD__HYS__DIS | PAD__PUS__100K_OHM_PD | PAD__PUE__PULL | PAD__PKE__EN  | PAD__ODE__DIS | PAD__SPEED__MEDIUM2 | PAD__DSE__43_OHM  | PAD__SRE__FAST)
				MX6QDL_PAD_DISP0_DAT23__GPIO5_IO17	(PAD__HYS__DIS | PAD__PUS__100K_OHM_PD | PAD__PUE__PULL | PAD__PKE__EN  | PAD__ODE__DIS | PAD__SPEED__MEDIUM2 | PAD__DSE__43_OHM  | PAD__SRE__FAST)
			>;
		};
	};
};
